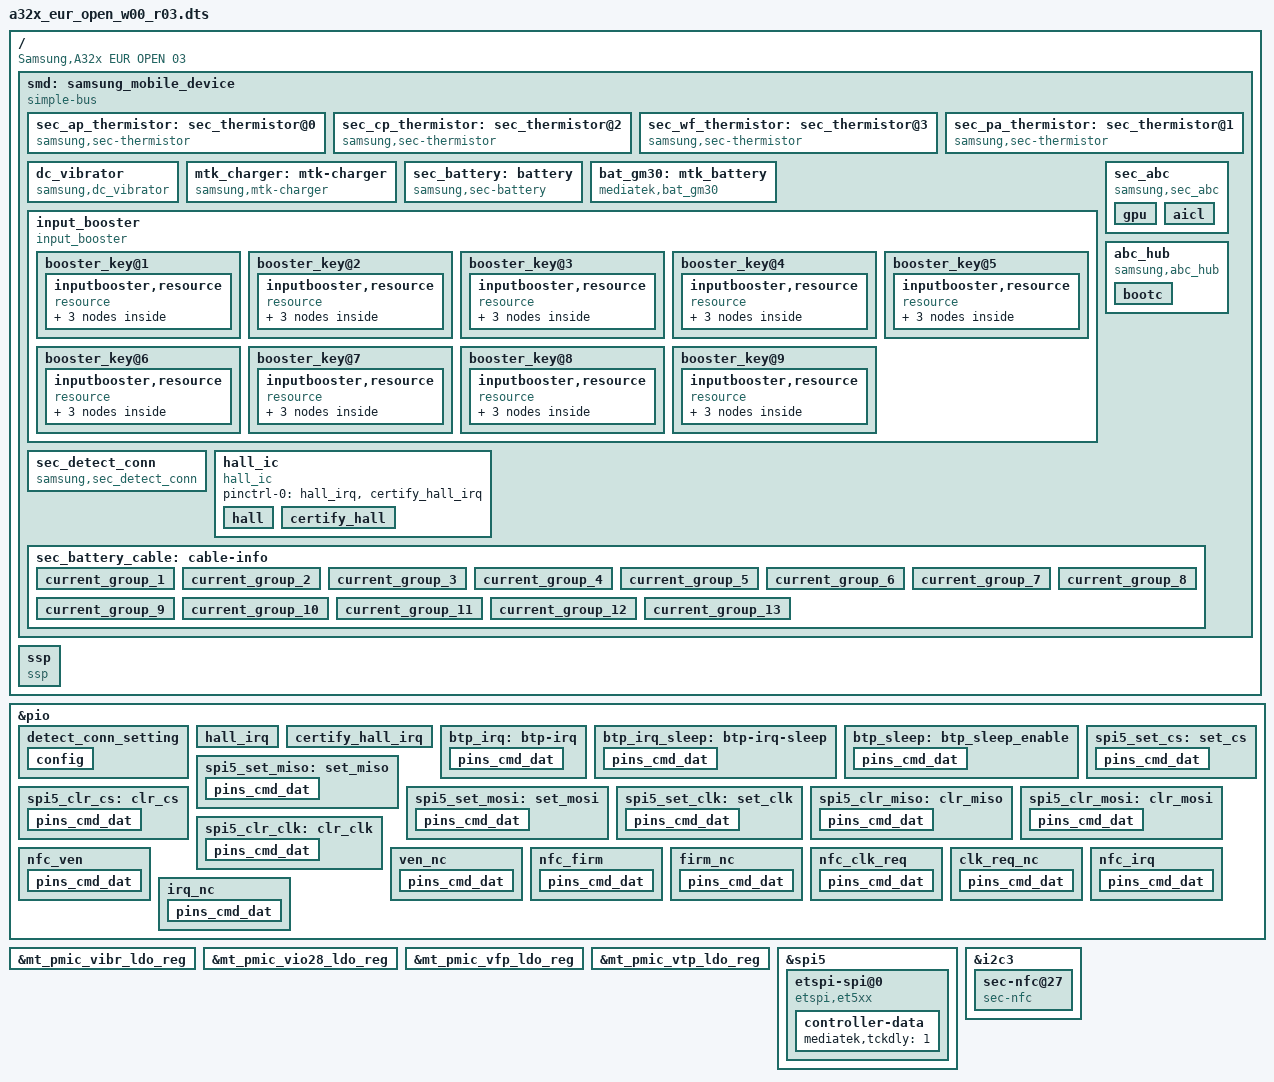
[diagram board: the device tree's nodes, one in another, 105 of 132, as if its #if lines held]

/*
 * Copyright (c) 2018 Samsung Electronics Co., Ltd.
 *              http://www.samsung.com
 *
 * This program is free software; you can redistribute it and/or modify
 * it under the terms of the GNU General Public License version 2 as
 * published by the Free Software Foundation.
*/

/dts-v1/;
/plugin/;
/ {
	fragment@smd {
		target-path = "/";
		__overlay__ {
			smd: samsung_mobile_device {
				compatible = "simple-bus";
			};
		};
	};
};

/* #include "../mtk_charger.dtsi" */                 /* From mtk_charger.py */

&smd {
	mtk_charger: mtk-charger {
		compatible = "samsung,mtk-charger";
		charger,vbus_min_charger_voltage = <4600000>;
		charger,vbus_normal_mivr_voltage = <4400000>;
		charger,gpio_ilim = <&pio 140 0x0>;
		charger,gpio_chgenb = <&pio 135 0x0>;
		charger,max_icl = <3250>;
		charger,ib_fcc = <100>;
	};
};

/* /home/dpi/qb5_8815/workspace/P4_1716/android/kernel/kmodule/battery/charger/mtk_charger/mtk_charger.a32x_eur_open.01.dtsi */

&smd {
	mtk_charger: mtk-charger {
		charger,chgenb_en = <1>;
	};
};


/* #include "../mtk_fuelgauge.dtsi" */               /* From mtk_fuelgauge.py */
&smd {
	battery {
		battery,fuelgauge_name = "mtk-fg-battery";
	};

	/* battery_prop.dtsi */
	bat_gm30: mtk_battery{
		compatible = "mediatek,bat_gm30";
		DIFFERENCE_FULLOCV_ITH = <(300)>;
	/*	Charging termination current*/
		SHUTDOWN_1_TIME = <(60)>;
	/*	If ui_soc shows 1% more than X minites, system will shutdown*/
		KEEP_100_PERCENT = <(1)>;
	/* 	The ui_soc will keep 100% until SOC drop X percents after unplugged */
		R_FG_VALUE = <(5)>;
	/*	R_sense resistance*/
		EMBEDDED_SEL = <(0)>;
	/*	Configures whether using embedded battery or not*/
		PMIC_SHUTDOWN_CURRENT = <(20)>;
	/*	System shutdown current*/
		FG_METER_RESISTANCE = <(100)>;
	/*	The resistance of PCB*/
		CAR_TUNE_VALUE = <(99)>;
	/*	Tune value for current measurement*/
		PMIC_MIN_VOL = <(33500)>;
	/*	vboot voltage for gauge 0%*/
		POWERON_SYSTEM_IBOOT = <(500)>;
	/*	power on system iboot*/
		SHUTDOWN_GAUGE0 = <(0)>;
	/*	Shutdown condition2 switch*/
		SHUTDOWN_GAUGE0_VOLTAGE = <(34000)>;
	/*	shutdown gauge 0% voltage*/
		TEMPERATURE_T0 = <(50)>;
	/*	Battery temperature T0*/
		TEMPERATURE_T1 = <(25)>;
	/*	Battery temperature T1*/
		TEMPERATURE_T2 = <(10)>;
	/*	Battery temperature T2*/
		TEMPERATURE_T3 = <(0)>;
	/*	Battery temperature T3*/
		TEMPERATURE_T4 = <(-10)>;
	/*	Battery temperature T4*/
		TEMPERATURE_T5 = <(-20)>;
	/*	Battery temperature T5*/
		g_FG_PSEUDO100_T0 = <(93)>;
	/*	Pseudo 100% percentage at T0*/
		g_FG_PSEUDO100_T1 = <(93)>;
	/*	Pseudo 100% percentage at T1*/
		g_FG_PSEUDO100_T2 = <(93)>;
	/*	Pseudo 100% percentage at T2*/
		g_FG_PSEUDO100_T3 = <(93)>;
	/*	Pseudo 100% percentage at T3*/
		g_FG_PSEUDO100_T4 = <(93)>;
	/*	Pseudo 100% percentage at T4*/
		g_FG_PSEUDO100_T5 = <(93)>;
	/*	Pseudo 100% percentage at T4*/
		Q_MAX_SYS_VOLTAGE_BAT0 = <(3350)>;
	/*	Pseudo1 for hide percentage*/
		Q_MAX_SYS_VOLTAGE_BAT1 = <(3350)>;
	/*	Pseudo1 for hide percentage*/
		Q_MAX_SYS_VOLTAGE_BAT2 = <(3350)>;
	/*	Pseudo1 for hide percentage*/
		Q_MAX_SYS_VOLTAGE_BAT3 = <(3350)>;
	/*	Pseudo1 for hide percentage*/
		COM_FG_METER_RESISTANCE = <(100)>;
	/*	compensate The resistance of PCB*/
		COM_R_FG_VALUE = <(0)>;
	/*	compensate R_sense resistance*/
		enable_tmp_intr_suspend = <(0)>;
	/* Enable update temp when suspend */
		ACTIVE_TABLE = <(6)>;
	/* Table numbers per battery*/
		MULTI_TEMP_GAUGE0 = <(1)>;
	/* Multi gauge0 enable*/
		HWOCV_OLDOCV_DIFF = <(100)>;
	/* Diff of HWOCV and SWOCV*/

	/* battery_table.dtsi*/
	battery0_profile_t0_num = <100>;
	battery0_profile_t0_col = <3>;
	battery0_profile_t0 =
	<
	0       43520   850
	486     43380   866
	972     43251   875
	1458    43130   897
	1944    43004   875
	2430    42881   875
	2916    42760   875
	3402    42644   875
	3888    42530   900
	4375    42407   875
	4861    42293   881
	5347    42178   900
	5833    42054   875
	6319    41941   897
	6805    41820   875
	7291    41714   875
	7777    41601   900
	8263    41485   875
	8749    41372   875
	9235    41267   897
	9721    41155   875
	10207   41051   875
	10693   40945   875
	11179   40837   884
	11665   40739   875
	12152   40642   900
	12638   40542   894
	13124   40446   919
	13610   40350   900
	14096   40253   900
	14582   40162   919
	15068   40070   925
	15554   39979   925
	16040   39898   941
	16526   39817   950
	17012   39736   950
	17498   39655   962
	17984   39573   975
	18470   39492   975
	18956   39411   1000
	19442   39329   1025
	19928   39210   975
	20415   39078   938
	20901   38949   878
	21387   38849   875
	21873   38773   850
	22359   38699   850
	22845   38635   850
	23331   38580   850
	23817   38521   850
	24303   38472   850
	24789   38423   850
	25275   38374   875
	25761   38326   850
	26247   38285   869
	26733   38239   850
	27219   38200   875
	27705   38157   866
	28192   38115   868
	28678   38082   872
	29164   38050   875
	29650   38007   853
	30136   37975   875
	30622   37952   900
	31108   37919   900
	31594   37887   900
	32080   37865   907
	32566   37841   925
	33052   37810   925
	33538   37765   900
	34024   37684   861
	34510   37614   865
	34996   37550   851
	35482   37511   859
	35968   37465   857
	36455   37424   853
	36941   37374   850
	37427   37337   875
	37913   37304   875
	38399   37272   875
	38885   37230   875
	39371   37185   900
	39857   37120   875
	40343   37063   875
	40829   37004   888
	41315   36942   879
	41801   36861   881
	42287   36806   860
	42773   36790   875
	43259   36780   891
	43745   36767   907
	44232   36751   948
	44718   36719   976
	45204   36643   1018
	45690   36372   937
	46176   35944   969
	46662   35387   1000
	47148   34581   1041
	47634   33318   1181
	48120   30130   10325
	>;
	battery0_profile_t1_num = <100>;
	battery0_profile_t1_col = <3>;
	battery0_profile_t1 =
	<
	0       43320   1450
	486     43164   1450
	972     43033   1475
	1458    42911   1475
	1944    42789   1475
	2430    42671   1475
	2916    42550   1456
	3402    42434   1475
	3888    42320   1475
	4375    42197   1440
	4861    42083   1431
	5347    41968   1428
	5833    41854   1437
	6319    41741   1428
	6805    41628   1431
	7291    41514   1425
	7777    41401   1425
	8263    41295   1425
	8749    41184   1407
	9235    41078   1403
	9721    40975   1412
	10207   40871   1425
	10693   40765   1425
	11179   40667   1416
	11665   40569   1425
	12152   40475   1450
	12638   40382   1450
	13124   40277   1450
	13610   40190   1450
	14096   40093   1447
	14582   40002   1444
	15068   39920   1460
	15554   39839   1450
	16040   39758   1450
	16526   39687   1500
	17012   39606   1500
	17498   39525   1500
	17984   39443   1504
	18470   39354   1525
	18956   39243   1490
	19442   39109   1425
	19928   38980   1344
	20415   38875   1319
	20901   38787   1300
	21387   38719   1313
	21873   38654   1300
	22359   38589   1300
	22845   38535   1290
	23331   38480   1300
	23817   38431   1291
	24303   38384   1300
	24789   38343   1300
	25275   38294   1300
	25761   38257   1303
	26247   38217   1325
	26733   38182   1309
	27219   38140   1325
	27705   38107   1341
	28192   38075   1332
	28678   38042   1350
	29164   38010   1350
	29650   37987   1375
	30136   37955   1375
	30622   37926   1375
	31108   37900   1376
	31594   37877   1384
	32080   37855   1400
	32566   37822   1378
	33052   37790   1375
	33538   37747   1375
	34024   37707   1356
	34510   37672   1360
	34996   37630   1351
	35482   37591   1359
	35968   37552   1350
	36455   37512   1372
	36941   37480   1375
	37427   37447   1375
	37913   37414   1394
	38399   37368   1385
	38885   37310   1376
	39371   37248   1393
	39857   37192   1400
	40343   37134   1423
	40829   37063   1412
	41315   36975   1425
	41801   36935   1425
	42287   36920   1460
	42773   36910   1475
	43259   36894   1500
	43745   36867   1514
	44232   36833   1573
	44718   36727   1613
	45204   36421   1607
	45690   35937   1688
	46176   35299   1804
	46662   34415   1951
	47148   32710   2488
	47634   30570   11550
	48120   30570   11550
	>;
	battery0_profile_t2_num = <100>;
	battery0_profile_t2_col = <3>;
	battery0_profile_t2 =
	<
	0       43000   3200
	486     42808   3293
	972     42661   3412
	1458    42531   3472
	1944    42404   3476
	2430    42281   3478
	2916    42160   3481
	3402    42044   3484
	3888    41930   3475
	4375    41817   3485
	4861    41695   3456
	5347    41579   3431
	5833    41474   3450
	6319    41361   3425
	6805    41255   3425
	7291    41144   3425
	7777    41041   3425
	8263    40931   3416
	8749    40834   3407
	9235    40737   3425
	9721    40640   3425
	10207   40541   3444
	10693   40435   3419
	11179   40337   3425
	11665   40229   3375
	12152   40138   3391
	12638   40047   3381
	13124   39957   3378
	13610   39875   3400
	14096   39794   3375
	14582   39712   3375
	15068   39640   3415
	15554   39559   3425
	16040   39472   3409
	16526   39382   3425
	17012   39269   3381
	17498   39146   3350
	17984   39008   3268
	18470   38894   3225
	18956   38801   3200
	19442   38720   3200
	19928   38655   3200
	20415   38590   3200
	20901   38534   3222
	21387   38479   3225
	21873   38426   3250
	22359   38377   3250
	22845   38329   3275
	23331   38280   3275
	23817   38241   3300
	24303   38202   3325
	24789   38162   3347
	25275   38130   3363
	25761   38087   3378
	26247   38055   3400
	26733   38022   3425
	27219   37990   3425
	27705   37967   3466
	28192   37935   3500
	28678   37911   3500
	29164   37885   3525
	29650   37859   3528
	30136   37842   3569
	30622   37822   3600
	31108   37800   3601
	31594   37784   3641
	32080   37757   3657
	32566   37732   3697
	33052   37700   3700
	33538   37667   3728
	34024   37627   3750
	34510   37592   3795
	34996   37559   3850
	35482   37517   3866
	35968   37482   3932
	36455   37434   3972
	36941   37374   4026
	37427   37314   4104
	37913   37249   4144
	38399   37190   4235
	38885   37119   4325
	39371   37028   4398
	39857   36965   4501
	40343   36932   4666
	40829   36905   4816
	41315   36877   5048
	41801   36845   5310
	42287   36790   5653
	42773   36689   6028
	43259   36466   6433
	43745   36033   6914
	44232   35419   7720
	44718   34544   8974
	45204   33115   11297
	45690   30950   12525
	46176   30950   12525
	46662   30950   12525
	47148   30950   12525
	47634   30950   12525
	48120   30950   12525
	>;
	battery0_profile_t3_num = <100>;
	battery0_profile_t3_col = <3>;
	battery0_profile_t3 =
	<
	0       42520   5950
	486     42262   6183
	972     42098   6518
	1458    41961   6640
	1944    41824   6714
	2430    41701   6753
	2916    41580   6775
	3402    41464   6816
	3888    41350   6825
	4375    41237   6840
	4861    41123   6825
	5347    41017   6847
	5833    40909   6825
	6319    40812   6847
	6805    40715   6844
	7291    40604   6825
	7777    40501   6825
	8263    40385   6784
	8749    40274   6782
	9235    40177   6800
	9721    40080   6800
	10207   39984   6778
	10693   39903   6781
	11179   39821   6784
	11665   39739   6800
	12152   39658   6791
	12638   39587   6825
	13124   39497   6803
	13610   39410   6813
	14096   39312   6797
	14582   39196   6756
	15068   39069   6680
	15554   38949   6625
	16040   38836   6584
	16526   38747   6569
	17012   38666   6550
	17498   38600   6575
	17984   38536   6579
	18470   38479   6600
	18956   38418   6635
	19442   38370   6675
	19928   38321   6691
	20415   38275   6706
	20901   38234   6725
	21387   38194   6750
	21873   38156   6775
	22359   38115   6794
	22845   38082   6835
	23331   38050   6850
	23817   38018   6891
	24303   37984   6907
	24789   37952   6925
	25275   37930   6975
	25761   37909   7003
	26247   37892   7044
	26733   37876   7084
	27219   37860   7125
	27705   37843   7183
	28192   37827   7214
	28678   37811   7295
	29164   37795   7351
	29650   37777   7407
	30136   37752   7488
	30622   37722   7544
	31108   37689   7626
	31594   37657   7723
	32080   37622   7813
	32566   37582   7939
	33052   37540   8076
	33538   37495   8238
	34024   37437   8422
	34510   37374   8610
	34996   37309   8853
	35482   37238   9080
	35968   37170   9352
	36455   37096   9676
	36941   37004   10017
	37427   36935   10393
	37913   36894   10858
	38399   36862   11389
	38885   36830   11982
	39371   36791   12670
	39857   36740   13453
	40343   36656   14301
	40829   36424   15025
	41315   35986   15823
	41801   35349   16953
	42287   34442   18475
	42773   33430   18575
	43259   33430   18575
	43745   33430   18575
	44232   33430   18575
	44718   33430   18575
	45204   33430   18575
	45690   33430   18575
	46176   33430   18575
	46662   33430   18575
	47148   33430   18575
	47634   33430   18575
	48120   33430   18575
	>;
	battery0_profile_t4_num = <100>;
	battery0_profile_t4_col = <3>;
	battery0_profile_t4 =
	<
	0       42010   11330
	486     41738   11604
	972     41429   12066
	1458    41171   12469
	1944    40989   12751
	2430    40838   12878
	2916    40700   12919
	3402    40570   12916
	3888    40440   12875
	4375    40311   12819
	4861    40181   12744
	5347    40058   12703
	5833    39949   12675
	6319    39842   12650
	6805    39745   12650
	7291    39648   12616
	7777    39541   12526
	8263    39441   12509
	8749    39332   12437
	9235    39227   12378
	9721    39115   12312
	10207   39013   12272
	10693   38923   12250
	11179   38841   12216
	11665   38759   12200
	12152   38694   12184
	12638   38622   12175
	13124   38565   12175
	13610   38510   12200
	14096   38456   12178
	14582   38407   12200
	15068   38358   12210
	15554   38310   12225
	16040   38261   12241
	16526   38215   12256
	17012   38174   12297
	17498   38140   12325
	17984   38097   12329
	18470   38065   12350
	18956   38032   12375
	19442   38010   12450
	19928   37977   12475
	20415   37955   12506
	20901   37931   12568
	21387   37905   12626
	21873   37874   12675
	22359   37855   12770
	22845   37832   12819
	23331   37800   12900
	23817   37778   13031
	24303   37744   13121
	24789   37712   13242
	25275   37670   13327
	25761   37626   13460
	26247   37577   13639
	26733   37535   13728
	27219   37480   13875
	27705   37420   14031
	28192   37359   14202
	28678   37294   14386
	29164   37230   14552
	29650   37155   14720
	30136   37090   14944
	30622   37028   15148
	31108   36979   15354
	31594   36947   15613
	32080   36905   15847
	32566   36863   16130
	33052   36790   16376
	33538   36673   16644
	34024   36429   16891
	34510   36018   17215
	34996   35399   17761
	35482   34431   18699
	35968   32802   17069
	36455   31080   12750
	36941   31080   12750
	37427   31080   12750
	37913   31080   12750
	38399   31080   12750
	38885   31080   12750
	39371   31080   12750
	39857   31080   12750
	40343   31080   12750
	40829   31080   12750
	41315   31080   12750
	41801   31080   12750
	42287   31080   12750
	42773   31080   12750
	43259   31080   12750
	43745   31080   12750
	44232   31080   12750
	44718   31080   12750
	45204   31080   12750
	45690   31080   12750
	46176   31080   12750
	46662   31080   12750
	47148   31080   12750
	47634   31080   12750
	48120   31080   12750
	>;
	battery0_profile_t5_num = <100>;
	battery0_profile_t5_col = <3>;
	battery0_profile_t5 =
	<
	0       40920   10780
	483     40610   11233
	967     40337   12231
	1450    40095   12975
	1933    39872   13686
	2417    39674   14479
	2900    39510   15208
	3383    39378   15667
	3867    39258   15931
	4350    39150   16075
	4833    39042   16178
	5317    38929   16164
	5800    38830   16208
	6283    38733   16319
	6767    38652   16378
	7250    38573   16404
	7733    38509   16464
	8217    38444   16519
	8700    38390   16625
	9183    38335   16666
	9667    38292   16706
	10150   38244   16725
	10633   38200   16750
	11117   38158   16752
	11600   38126   16810
	12083   38087   16833
	12567   38052   16965
	13050   38019   16990
	13533   37987   17100
	14017   37955   17176
	14500   37919   17218
	14983   37880   17323
	15467   37838   17390
	15950   37794   17510
	16433   37738   17550
	16917   37683   17714
	17400   37629   17828
	17883   37564   17981
	18367   37500   18070
	18850   37427   18222
	19333   37361   18385
	19817   37286   18407
	20300   37222   18563
	20783   37158   18764
	21267   37093   18919
	21750   37039   19080
	22233   36974   19247
	22717   36910   19451
	23200   36824   19655
	23683   36692   19921
	24167   36470   20134
	24650   36118   20420
	25133   35546   20803
	25617   34662   21167
	26100   33270   18200
	26583   32530   16450
	27067   32530   16450
	27550   32530   16450
	28033   32530   16450
	28517   32530   16450
	29000   32530   16450
	29483   32530   16450
	29967   32530   16450
	30450   32530   16450
	30933   32530   16450
	31417   32530   16450
	31900   32530   16450
	32383   32530   16450
	32867   32530   16450
	33350   32530   16450
	33833   32530   16450
	34317   32530   16450
	34800   32530   16450
	35283   32530   16450
	35767   32530   16450
	36250   32530   16450
	36733   32530   16450
	37217   32530   16450
	37700   32530   16450
	38183   32530   16450
	38667   32530   16450
	39150   32530   16450
	39633   32530   16450
	40117   32530   16450
	40600   32530   16450
	41083   32530   16450
	41567   32530   16450
	42050   32530   16450
	42533   32530   16450
	43017   32530   16450
	43500   32530   16450
	43983   32530   16450
	44467   32530   16450
	44950   32530   16450
	45433   32530   16450
	45917   32530   16450
	46400   32530   16450
	46883   32530   16450
	47367   32530   16450
	47850   32530   16450
	>;

	/* battery_prop_dim2_ext.dtsi */
	/*vboot voltage for gauge 0%*/
	g_PMIC_MIN_VOL_row = <4>;
	g_PMIC_MIN_VOL_col = <10>;
	g_PMIC_MIN_VOL =
	<
		32700  32700  32700  32700
		32700  32700  32700  32700
		32700  32700  32700  32700
		32200  32200  32200  32200
		31000  31000  31000  31000
		31500  31500  31500  31500
		31000  31000  31000  31000
		31000  31000  31000  31000
		31000  31000  31000  31000
		31000  31000  31000  31200
	>;
	/*boot_up current for gauge 0%*/
	g_PON_SYS_IBOOT_row = <4>;
	g_PON_SYS_IBOOT_col = <10>;
	g_PON_SYS_IBOOT =
	<
		5000  5000  5000  5000
		5000  5000  5000  5000
		5000  5000  5000  5000
		5000  5000  5000  5000
		5000  5000  5000  5000
		5000  5000  5000  5000
		5000  5000  5000  5000
		5000  5000  5000  5000
		5000  5000  5000  5000
		5000  5000  5000  5000
	>;
	/*Pseudo1 hide percentage*/
	g_QMAX_SYS_VOL_row = <4>;
	g_QMAX_SYS_VOL_col = <10>;
	g_QMAX_SYS_VOL =
	<
		33600  33600  33600  33600
		33600  33600  33600  33600
		33600  33600  33600  33600
		33600  33600  33600  33600
		33600  33600  33600  33600
		32500  32500  32500  32500
		32800  32800  32800  32800
		32800  32800  32800  32800
		32800  32800  32800  32800
		32800  32800  32800  32800
	>;
	/*Pseudo100 percentage setting*/
	g_FG_PSEUDO100_row = <4>;
	g_FG_PSEUDO100_col = <10>;
	g_FG_PSEUDO100 =
	<
		 93  100  100  100
		 93  100  100  100
		 93  100  100  100
		 93  100  100  100
		 93  100  100  100
		 93  100  100  100
		100  100  100  100
		100  100  100  100
		100  100  100  100
		100  100  100  100
	>;

	};
};

/* /home/dpi/qb5_8815/workspace/P4_1716/android/kernel/kmodule/battery/fuelgauge/mtk_fuelgauge/mtk_fuelgauge.a32x_eur_open.01.dtsi */
&smd {
	bat_gm30: mtk_battery{
		/* The ui_soc will keep 100% until SOC drop X percents after unplugged */
		R_FG_VALUE = <(5)>;
	};
};

/* #include "../sec_pinctrl_wrapper.dtsi" */         /* From sec_pinctrl_wrapper.py */
#define PIN_FUNC_INPUT		input-enable
#define PIN_FUNC_INPUT_WAKEUP	input-enable
#define PIN_FUNC_OUTPUT		output-enable
#define PIN_FUNC_OUTPUT_HIGH		output-high
#define PIN_FUNC_OUTPUT_LOW		output-low

#define PIN_PULL_NONE	bias-disable
#define PIN_PULL_DOWN	bias-pull-down
#define PIN_PULL_UP	bias-pull-up
#define PIN_PULL_OPEN	bias-high-impedance

/*
 * MTK_DRIVE_2mA  2
 * MTK_DRIVE_4mA  4
 * MTK_DRIVE_6mA  6
 * MTK_DRIVE_8mA  8
 * MTK_DRIVE_10mA 10
 * MTK_DRIVE_12mA 12
 * MTK_DRIVE_14mA 14
 * MTK_DRIVE_16mA 16
 */

#define PIN_DRV_LV1	2
#define PIN_DRV_LV2	4
#define PIN_DRV_LV3	6
#define PIN_DRV_LV4	8
#define PIN_DRV_LV5	10
#define PIN_DRV_LV6	12
#define PIN_DRV_LV7	14
#define PIN_DRV_LV8	16

#define PIN_EXPAND(pin) #pin

#define SEC_GPIO(src, type, num)	PIN_EXPAND(gpio##num)
#define SEC_GPIO_REF(src, type, num)	&type num
#define SEC_GPIO_NUM(src, type, num)	num
#define SEC_GPIO_TYPE(src, type, num)	&type

#define MTK_PINMUX(gpio, func) (MTK_PIN_NO(gpio) | func)

#define GPIO_CONFIG(_src, _type, _num, _func)		\
	pins_cmd_dat{					\
		pinmux = <MTK_PINMUX(SEC_GPIO_NUM(_src, _type, _num), 0)>;	\
		PIN_ ##_func;		\
	}

#define GPIO_CONFIG_PUD(_src, _type, _num, _func, _pull)	\
	pins_cmd_dat{					\
		pinmux = <MTK_PINMUX(SEC_GPIO_NUM(_src, _type, _num), 0)>;	\
		PIN_ ##_pull;				\
		PIN_ ##_func;		\
	}

#define GPIO_CONFIG_PUD_DRV(_src, _type, _num, _func, _pull, _drv)	\
	pins_cmd_dat{					\
		pinmux = <MTK_PINMUX(SEC_GPIO_NUM(_src, _type, _num), 0)>;	\
		PIN_ ##_pull;				\
		PIN_ ##_func;		\
		drive-strength = <PIN_ ##_drv>;	\
	}

#define SEC_ADC(type, num) <&type num>
#define SEC_ADC_OPT(type, num) ,<&type num>
#define SEC_ADC_NUM(type, num) <num>

/* #include "../input_booster.dtsi" */               /* From input_booster.py */
/* Copyright (c) 2019, The Linux Foundation. All rights reserved.
 *
 * This program is free software; you can redistribute it and/or modify
 * it under the terms of the GNU General Public License version 2 and
 * only version 2 as published by the Free Software Foundation.
 *
 * This program is distributed in the hope that it will be useful,
 * but WITHOUT ANY WARRANTY; without even the implied warranty of
 * MERCHANTABILITY or FITNESS FOR A PARTICULAR PURPOSE.  See the
 * GNU General Public License for more details.
 */

&smd {
	input_booster {
		status = "okay";
		compatible = "input_booster";
		resValcount = "2";
		max_resource_count = "3";
		max_cluster_count = "3";
		#address-cells = <1>;
		#size-cells = <0>;

		/* Each Cpu Cluster Start Cpu */
		cpu_cluster_policy = "6,0";

		/* < CPU, DDR, SCHEDBOOST > */
		ib_release_values = "-1,16,0";

		/* Select Allowed Resource Index Group */
		allowed_resources = "0,1,2";

		booster_key@1 {
			input_booster,label = "key";
			input_booster,type = <0>;	/* BOOSTER_DEVICE_KEY */

			/* Time table */
			input_booster,head_time = <200>;
			input_booster,tail_time = <0>;

			/* Resource Table Sequentially identified with index
			 * CPU's ID & Index : 0
			 * DDR's ID & Index : 1
			*/

			/* Input Booster Resource Frequency */
			inputbooster,resource {
				compatible = "resource";
				resource@1 {
					resource,label = "CPU";
					resource,value = <1274000 0>;
				};

				resource@2 {
					resource,label = "DDR";
					resource,value = <0 0>;
				};

				resource@3 {
					resource,label = "SCHEDBOOST";
					resource,value = <0 0>;
				};
			};
		};

		booster_key@2 {
			input_booster,label = "touchkey";
			input_booster,type = <1>;	/* BOOSTER_DEVICE_TOUCHKEY */

			/* Time table */
			input_booster,head_time = <1>;
			input_booster,tail_time = <300>;

			/* Input Booster Resource Frequency */
			inputbooster,resource {
				compatible = "resource";
				resource@1 {
					resource,label = "CPU";
					resource,value = <0 1075200>;
				};

				resource@2 {
					resource,label = "DDR";
					resource,value = <0 0>;
				};

				resource@3 {
					resource,label = "SCHEDBOOST";
					resource,value = <0 0>;
				};
			};
		};

		booster_key@3 {
			input_booster,label = "touch";
			input_booster,type = <2>;	/* BOOSTER_DEVICE_TOUCH */

			/* Time table */
			input_booster,head_time = <130>;
			input_booster,tail_time = <500>;

			/* Input Booster Resource Frequency */
			inputbooster,resource {
				compatible = "resource";
				resource@1 {
					resource,label = "CPU";
					resource,value = <1274000 1075200>;
				};

				resource@2 {
					resource,label = "DDR";
					resource,value = <4266 4266>;
				};

				resource@3 {
					resource,label = "SCHEDBOOST";
					resource,value = <3 0>;
				};
			};
		};

		booster_key@4 {
			input_booster,label = "multitouch";
			input_booster,type = <3>;	/* BOOSTER_DEVICE_MULTITOUCH */

			/* Time table */
			input_booster,head_time = <1000>;
			input_booster,tail_time = <500>;

			/* Input Booster Resource Frequency */
			inputbooster,resource {
				compatible = "resource";
				resource@1 {
					resource,label = "CPU";
					resource,value = <1274000 1075200>;
				};

				resource@2 {
					resource,label = "DDR";
					resource,value = <0 0>;
				};

				resource@3 {
					resource,label = "SCHEDBOOST";
					resource,value = <0 0>;
				};
			};
		};

		booster_key@5 {
			input_booster,label = "keyboard";
			input_booster,type = <4>;	/* BOOSTER_DEVICE_KEYBOARD */

			/* Time table */
			input_booster,head_time = <130>;
			input_booster,tail_time = <130>;

			/* Input Booster Resource Frequency */
			inputbooster,resource {
				compatible = "resource";
				resource@1 {
					resource,label = "CPU";
					resource,value = <1075200 1075200>;
				};

				resource@2 {
					resource,label = "DDR";
					resource,value = <0 0>;
				};

				resource@3 {
					resource,label = "SCHEDBOOST";
					resource,value = <0 0>;
				};
			};
		};

		booster_key@6 {
			input_booster,label = "MOUSE";
			input_booster,type = <5>;	/* BOOSTER_DEVICE_MOUSE */

			/* Time table */
			input_booster,head_time = <200>;
			input_booster,tail_time = <300>;

			/* Input Booster Resource Frequency */
			inputbooster,resource {
				compatible = "resource";
				resource@1 {
					resource,label = "CPU";
					resource,value = <1274000 1075200>;
				};

				resource@2 {
					resource,label = "DDR";
					resource,value = <0 0>;
				};

				resource@3 {
					resource,label = "SCHEDBOOST";
					resource,value = <0 0>;
				};
			};
		};

		booster_key@7 {
			input_booster,label = "mouse_wheel";
			input_booster,type = <6>;	/* BOOSTER_DEVICE_MOUSE */

			/* Time table */
			input_booster,head_time = <200>;
			input_booster,tail_time = <0>;

			/* Input Booster Resource Frequency */
			inputbooster,resource {
				compatible = "resource";
				resource@1 {
					resource,label = "CPU";
					resource,value = <1274000 0>;
				};

				resource@2 {
					resource,label = "DDR";
					resource,value = <0 0>;
				};

				resource@3 {
					resource,label = "SCHEDBOOST";
					resource,value = <0 0>;
				};
			};
		};

		booster_key@8 {
			input_booster,label = "pen_hover";
			input_booster,type = <7>;	/* BOOSTER_DEVICE_MOUSE */

			/* Time table */
			input_booster,head_time = <200>;
			input_booster,tail_time = <300>;

			/* Input Booster Resource Frequency */
			inputbooster,resource {
				compatible = "resource";
				resource@1 {
					resource,label = "CPU";
					resource,value = <1274000 1075200>;
				};

				resource@2 {
					resource,label = "DDR";
					resource,value = <0 0>;
				};

				resource@3 {
					resource,label = "SCHEDBOOST";
					resource,value = <0 0>;
				};
			};
		};

		booster_key@9 {
			input_booster,label = "pen";
			input_booster,type = <8>;	/* BOOSTER_DEVICE_MOUSE */

			/* Time table */
			input_booster,head_time = <200>;
			input_booster,tail_time = <600>;

			/* Input Booster Resource Frequency */
			inputbooster,resource {
				compatible = "resource";
				resource@1 {
					resource,label = "CPU";
					resource,value = <1720000 1075200>;
				};

				resource@2 {
					resource,label = "DDR";
					resource,value = <0 0>;
				};

				resource@3 {
					resource,label = "SCHEDBOOST";
					resource,value = <0 0>;
				};
			};
		};
		/* If you need to add new key type, add it this position */
	};
};

/* #include "../sti_abc.dtsi" */                     /* From sti_abc.py */
#ifndef CONFIG_SEC_FACTORY

#if 0
&${gpio_sub_connect_conn_parent} {
	sub_detect_conn_setting: sub-detect-conn-setting {
		samsung,pins = SEC_GPIO(${gpio_sub_connect_conn});
		samsung,pin-function = <0xf>;
		samsung,pin-pud = <0>;
		samsung,pin-drv = <0>;
	};
};
#endif

#if 0
&${gpio_sub_connect_conn_parent2} {
	sub_detect_conn_setting2: sub-detect-conn-setting2 {
		samsung,pins = SEC_GPIO(${gpio_sub_connect_conn2});
		samsung,pin-function = <0xf>;
		samsung,pin-pud = <0>;
		samsung,pin-drv = <0>;
	};
};
#endif

#if 0
&${gpio_cam_connect_conn_parent} {
	cam_detect_conn_setting: cam-detect-conn-setting {
		samsung,pins = SEC_GPIO(${gpio_cam_connect_conn});
		samsung,pin-function = <0xf>;
		samsung,pin-pud = <0>;
		samsung,pin-drv = <0>;
	};
};
#endif

#if 0
&${det_gpio_num_parent} {
	detect_conn_setting: detect_conn_setting {
		config {
#if 0
			pins = SEC_GPIO(${det_gpio_num_0}),
			       SEC_GPIO(${det_gpio_num_1}),
			       SEC_GPIO(${det_gpio_num_2}),
			       SEC_GPIO(${det_gpio_num_3}),
			       SEC_GPIO(${det_gpio_num_4}),
#if 0
			       SEC_GPIO(${det_gpio_num_5}),
			       SEC_GPIO(${det_gpio_num_6}),
			       SEC_GPIO(${det_gpio_num_7});
#elif 0
			       SEC_GPIO(${det_gpio_num_5}),
			       SEC_GPIO(${det_gpio_num_6});
#else
			       SEC_GPIO(${det_gpio_num_5});
#endif
#elif 0
			pins = SEC_GPIO(${det_gpio_num_0}),
			       SEC_GPIO(${det_gpio_num_1}),
			       SEC_GPIO(${det_gpio_num_2}),
			       SEC_GPIO(${det_gpio_num_3}),
#if 0
			       SEC_GPIO(${det_gpio_num_4}),
			       SEC_GPIO(${det_gpio_num_6}),
			       SEC_GPIO(${det_gpio_num_7});
#elif 0
			       SEC_GPIO(${det_gpio_num_4}),
			       SEC_GPIO(${det_gpio_num_6});
#else
			       SEC_GPIO(${det_gpio_num_4});
#endif
#elif 0
			pins = SEC_GPIO(${det_gpio_num_0}),
			       SEC_GPIO(${det_gpio_num_1}),
			       SEC_GPIO(${det_gpio_num_2}),
#if 0
			       SEC_GPIO(${det_gpio_num_3}),
			       SEC_GPIO(${det_gpio_num_6}),
			       SEC_GPIO(${det_gpio_num_7});
#elif 0
			       SEC_GPIO(${det_gpio_num_3}),
			       SEC_GPIO(${det_gpio_num_6});
#else
			       SEC_GPIO(${det_gpio_num_3});
#endif
#elif 0
			pins = SEC_GPIO(${det_gpio_num_0}),
			       SEC_GPIO(${det_gpio_num_1}),
#if 0
			       SEC_GPIO(${det_gpio_num_2}),
			       SEC_GPIO(${det_gpio_num_6}),
			       SEC_GPIO(${det_gpio_num_7});
#elif 0
			       SEC_GPIO(${det_gpio_num_2}),
			       SEC_GPIO(${det_gpio_num_6});
#else
			       SEC_GPIO(${det_gpio_num_2});
#endif
#elif 0
			pins = SEC_GPIO(${det_gpio_num_0}),
#if 0
			       SEC_GPIO(${det_gpio_num_1}),
			       SEC_GPIO(${det_gpio_num_6}),
			       SEC_GPIO(${det_gpio_num_7});
#elif 0
			       SEC_GPIO(${det_gpio_num_1}),
			       SEC_GPIO(${det_gpio_num_6});
#else
			       SEC_GPIO(${det_gpio_num_1});
#endif
#elif 0
			pins =
#if 0
			       SEC_GPIO(${det_gpio_num_0}),
			       SEC_GPIO(${det_gpio_num_6}),
			       SEC_GPIO(${det_gpio_num_7});
#elif 0
			       SEC_GPIO(${det_gpio_num_0}),
			       SEC_GPIO(${det_gpio_num_6});
#else
			       SEC_GPIO(${det_gpio_num_0});
#endif
#elif 0
			pins = SEC_GPIO(${det_gpio_num_6}),
			       SEC_GPIO(${det_gpio_num_7});
#elif 0
			pins = SEC_GPIO(${det_gpio_num_6});
#endif
			drive-strength = <2>;
			bias-disable; /*NO PULL*/
			input-enable;
		};
	};
};
#endif /*use_dynamic_ap_gpio_detect*/

#if 0
&${det_pm_gpio_num_parent} {
	detect_conn_pm_setting: detect_conn_pm_setting {
#if 0 && 0
		pins = SEC_GPIO(${det_pm_gpio_num_0}),
		       SEC_GPIO(${det_pm_gpio_num_1});
#elif 0
		pins = SEC_GPIO(${det_pm_gpio_num_0});
#elif 0
		pins = SEC_GPIO(${det_pm_gpio_num_1});
#endif
		function = "normal";
		power-source = <0>;
		bias-disable; /*NO PULL*/
		input-enable;
	};
};
#endif /*use_dynamic_pm_gpio_detect*/

#endif /* not CONFIG_SEC_FACTORY */

&smd {
	sec_abc {
		compatible = "samsung,sec_abc";
		status = "okay";

		gpu {
			gpu,label="GPU fault";
#if 0
			gpu,threshold_count=<4>;
			gpu,threshold_time=<1200>;
#else
			gpu,threshold_count=<20>;
			gpu,threshold_time=<1200>;
#endif
		};
#if 0
		gpu_page {
			gpu_page,label="GPU page fault";
			gpu_page,threshold_count=<20>;
			gpu_page,threshold_time=<1200>;
		};
#endif
		aicl {
			aicl,label="battery aicl";
			aicl,threshold_count=<5>;
			aicl,threshold_time=<300>;
		};
#if 0
		mipi_overflow {
			mipi_overflow,label="MIPI Overflow";
			mipi_overflow,threshold_count=<${mipi_overflow_threshold_count}>;
			mipi_overflow,threshold_time=<${mipi_overflow_threshold_time}>;
		};
#endif
#if 0
		motto {
			motto,label="motto info base";
			motto,info_bootcheck_base = <0x15860858>;
			motto,info_device_base = <0x1586085C>;
		};
#endif
	};
	abc_hub {
		compatible = "samsung,abc_hub";
		status = "okay";

#ifndef CONFIG_SEC_FACTORY
#if 0
#if 0 && 0
		pinctrl-names = "det_ap_connect","det_pm_connect";
		pinctrl-0 = <&detect_conn_setting>;
		pinctrl-1 = <&detect_conn_pm_setting>;
#elif 0
		pinctrl-names = "det_ap_connect";
		pinctrl-0 = <&detect_conn_setting>;
#elif 0
		pinctrl-names = "det_pm_connect";
		pinctrl-0 = <&detect_conn_pm_setting>;
#endif
/*not feature_abc_qcom_dt*/
#elif 0 && 0 && 0
		pinctrl-0 = <&sub_detect_conn_setting &sub_detect_conn_setting2 &cam_detect_conn_setting>;
#elif 0 && 0
		pinctrl-0 = <&sub_detect_conn_setting &cam_detect_conn_setting>;
#elif 0 && 0
		pinctrl-0 = <&sub_detect_conn_setting &sub_detect_conn_setting2>;
#elif 0
		pinctrl-0 = <&sub_detect_conn_setting>;
#elif 0
		pinctrl-0 = <&cam_detect_conn_setting>;
#endif
#endif /* not CONFIG_SEC_FACTORY */
		bootc {
			bootc,time_spec_user = <100000>; /* user binary user build */
			bootc,time_spec_eng = <100000>; /* user binary eng build */
			bootc,time_spec_fac = <100000>; /* factory binary */
		};

#ifndef CONFIG_SEC_FACTORY
#if 0
#if 0 || 0
		cond {
#if 0
			sec,det_conn_gpios = <
#if 0
					SEC_GPIO_REF(${det_gpio_num_0}) 0
#endif
#if 0
					SEC_GPIO_REF(${det_gpio_num_1}) 0
#endif
#if 0
					SEC_GPIO_REF(${det_gpio_num_2}) 0
#endif
#if 0
					SEC_GPIO_REF(${det_gpio_num_3}) 0
#endif
#if 0
					SEC_GPIO_REF(${det_gpio_num_4}) 0
#endif
#if 0
					SEC_GPIO_REF(${det_gpio_num_5}) 0
#endif
#if 0
					SEC_GPIO_REF(${det_gpio_num_6}) 0
#endif
#if 0
					SEC_GPIO_REF(${det_gpio_num_7}) 0
#endif
					>;
#if 0 || 0
			sec,det_conn_name =
#endif
#if 0 && 0
					"", "", "", "", "", "",
					"", "";
#elif 0
					"", "", "", "", "", "";
#elif 0
					"", "";
#endif
#endif /*use_dynamic_ap_gpio_detect*/

#if 0
			sec,det_pm_conn_gpios = <
#if 0
					SEC_GPIO_REF(${det_pm_gpio_num_0}) 0
#endif
#if 0
					SEC_GPIO_REF(${det_pm_gpio_num_1}) 0
#endif
					>;
#if 0 || 0
			sec,det_pm_conn_name =
#endif
#if 0 && 0
					"",
					"";
#elif 0
					"";
#elif 0
					"";
#endif
#endif /*use_dynamic_pm_gpio_detect */
		};
#endif /*use_dynamic_ap_gpio_detect || use_dynamic_pm_gpio_detect*/

/*not feature_abc_qcom_dt, feature_abc_lsi_dt*/
#elif 0 && 0 && 0
		cond {
			sec,det_conn_gpios = <SEC_GPIO_REF(${gpio_sub_connect_conn}) 0
						SEC_GPIO_REF(${gpio_sub_connect_conn2}) 0
						SEC_GPIO_REF(${gpio_cam_connect_conn}) 0>;
			sec,det_conn_name = "sub", "sub2", "cam";
			sec,det_conn_irq_type = <3>; /* BOTH EDGE */
		};
#elif 0 && 0
		cond {
			sec,det_conn_gpios = <SEC_GPIO_REF(${gpio_sub_connect_conn}) 0
						SEC_GPIO_REF(${gpio_cam_connect_conn}) 0>;
			sec,det_conn_name = "sub", "cam";
			sec,det_conn_irq_type = <3>; /* BOTH EDGE */
		};
#elif 0 && 0
		cond {
			sec,det_conn_gpios = <SEC_GPIO_REF(${gpio_sub_connect_conn}) 0
						SEC_GPIO_REF(${gpio_sub_connect_conn2}) 0>;
			sec,det_conn_name = "sub", "sub2";
			sec,det_conn_irq_type = <3>; /* BOTH EDGE */
		};
#elif 0
		cond {
			sec,det_conn_gpios = <SEC_GPIO_REF(${gpio_sub_connect_conn}) 0>;
			sec,det_conn_name = "sub";
			sec,det_conn_irq_type = <3>; /* BOTH EDGE */
		};
#elif 0
		cond {
			sec,det_conn_gpios = <SEC_GPIO_REF(${gpio_cam_connect_conn}) 0>;
			sec,det_conn_name = "cam";
			sec,det_conn_irq_type = <3>; /* BOTH EDGE */
		};
#endif
#endif /* not CONFIG_SEC_FACTORY */
	};
};

/* #include "../ap_mtk_mt6853.dtsi" */               /* From ap_mtk_mt6853.py */
#include <dt-bindings/clock/mt6853-clk.h>
#include "../../mediatek/k6853v1_64_titan.dts"


/* #include "../gpio_sec_detect_conn.dtsi" */        /* From gpio_sec_detect_conn.py */
#ifdef CONFIG_SEC_FACTORY
#if 1
&pio {
	detect_conn_setting: detect_conn_setting {
		config {
#if 0
			pinmux = <MTK_PINMUX(SEC_GPIO_NUM(AP,pio,69), 0)>,
			       <MTK_PINMUX(SEC_GPIO_NUM(${det_gpio_num_1}), 0)>,
			       <MTK_PINMUX(SEC_GPIO_NUM(${det_gpio_num_2}), 0)>,
			       <MTK_PINMUX(SEC_GPIO_NUM(${det_gpio_num_3}), 0)>,
			       <MTK_PINMUX(SEC_GPIO_NUM(${det_gpio_num_4}), 0)>,
#if 0
			       <MTK_PINMUX(SEC_GPIO_NUM(${det_gpio_num_5}), 0)>,
			       <MTK_PINMUX(SEC_GPIO_NUM(${det_gpio_num_6}), 0)>,
			       <MTK_PINMUX(SEC_GPIO_NUM(${det_gpio_num_7}), 0)>;
#elif 0
			       <MTK_PINMUX(SEC_GPIO_NUM(${det_gpio_num_5}), 0)>,
			       <MTK_PINMUX(SEC_GPIO_NUM(${det_gpio_num_6}), 0)>;
#else
			       <MTK_PINMUX(SEC_GPIO_NUM(${det_gpio_num_5}), 0)>;
#endif
#elif 0
			pinmux = <MTK_PINMUX(SEC_GPIO_NUM(AP,pio,69), 0)>,
			       <MTK_PINMUX(SEC_GPIO_NUM(${det_gpio_num_1}), 0)>,
			       <MTK_PINMUX(SEC_GPIO_NUM(${det_gpio_num_2}), 0)>,
			       <MTK_PINMUX(SEC_GPIO_NUM(${det_gpio_num_3}), 0)>,
#if 0
			       <MTK_PINMUX(SEC_GPIO_NUM(${det_gpio_num_4}), 0)>,
			       <MTK_PINMUX(SEC_GPIO_NUM(${det_gpio_num_6}), 0)>,
			       <MTK_PINMUX(SEC_GPIO_NUM(${det_gpio_num_7}), 0)>;
#elif 0
			       <MTK_PINMUX(SEC_GPIO_NUM(${det_gpio_num_4}), 0)>,
			       <MTK_PINMUX(SEC_GPIO_NUM(${det_gpio_num_6}), 0)>;
#else
			       <MTK_PINMUX(SEC_GPIO_NUM(${det_gpio_num_4}), 0)>;
#endif
#elif 0
			pinmux = <MTK_PINMUX(SEC_GPIO_NUM(AP,pio,69), 0)>,
			       <MTK_PINMUX(SEC_GPIO_NUM(${det_gpio_num_1}), 0)>,
			       <MTK_PINMUX(SEC_GPIO_NUM(${det_gpio_num_2}), 0)>,
#if 0
			       <MTK_PINMUX(SEC_GPIO_NUM(${det_gpio_num_3}), 0)>,
			       <MTK_PINMUX(SEC_GPIO_NUM(${det_gpio_num_6}), 0)>,
			       <MTK_PINMUX(SEC_GPIO_NUM(${det_gpio_num_7}), 0)>;
#elif 0
			       <MTK_PINMUX(SEC_GPIO_NUM(${det_gpio_num_3}), 0)>,
			       <MTK_PINMUX(SEC_GPIO_NUM(${det_gpio_num_6}), 0)>;
#else
			       <MTK_PINMUX(SEC_GPIO_NUM(${det_gpio_num_3}), 0)>;
#endif
#elif 0
			pinmux = <MTK_PINMUX(SEC_GPIO_NUM(AP,pio,69), 0)>,
			       <MTK_PINMUX(SEC_GPIO_NUM(${det_gpio_num_1}), 0)>,
#if 0
			       <MTK_PINMUX(SEC_GPIO_NUM(${det_gpio_num_2}), 0)>,
			       <MTK_PINMUX(SEC_GPIO_NUM(${det_gpio_num_6}), 0)>,
			       <MTK_PINMUX(SEC_GPIO_NUM(${det_gpio_num_7}), 0)>;
#elif 0
			       <MTK_PINMUX(SEC_GPIO_NUM(${det_gpio_num_2}), 0)>,
			       <MTK_PINMUX(SEC_GPIO_NUM(${det_gpio_num_6}), 0)>;
#else
			       <MTK_PINMUX(SEC_GPIO_NUM(${det_gpio_num_2}), 0)>;
#endif
#elif 0
			pinmux = <MTK_PINMUX(SEC_GPIO_NUM(AP,pio,69), 0)>,
#if 0
			       <MTK_PINMUX(SEC_GPIO_NUM(${det_gpio_num_1}), 0)>,
			       <MTK_PINMUX(SEC_GPIO_NUM(${det_gpio_num_6}), 0)>,
			       <MTK_PINMUX(SEC_GPIO_NUM(${det_gpio_num_7}), 0)>;
#elif 0
			       <MTK_PINMUX(SEC_GPIO_NUM(${det_gpio_num_1}), 0)>,
			       <MTK_PINMUX(SEC_GPIO_NUM(${det_gpio_num_6}), 0)>;
#else
			       <MTK_PINMUX(SEC_GPIO_NUM(${det_gpio_num_1}), 0)>;
#endif
#elif 1
			pinmux =
#if 0
			       <MTK_PINMUX(SEC_GPIO_NUM(AP,pio,69), 0)>,
			       <MTK_PINMUX(SEC_GPIO_NUM(${det_gpio_num_6}), 0)>,
			       <MTK_PINMUX(SEC_GPIO_NUM(${det_gpio_num_7}), 0)>;
#elif 0
			       <MTK_PINMUX(SEC_GPIO_NUM(AP,pio,69), 0)>,
			       <MTK_PINMUX(SEC_GPIO_NUM(${det_gpio_num_6}), 0)>;
#else
			       <MTK_PINMUX(SEC_GPIO_NUM(AP,pio,69), 0)>;
#endif
#elif 0
			pinmux = <MTK_PINMUX(SEC_GPIO_NUM(${det_gpio_num_6}), 0)>,
			       <MTK_PINMUX(SEC_GPIO_NUM(${det_gpio_num_7}), 0)>;
#elif 0
			pinmux = <MTK_PINMUX(SEC_GPIO_NUM(${det_gpio_num_6}), 0)>;
#endif
			drive-strength = <2>;
			bias-disable; /*NO PULL*/
			input-enable;
		};
	};
};
#endif /*use_dynamic_ap_gpio_detect*/

#if 0
&${det_pm_gpio_num_parent} {
	detect_conn_pm_setting: detect_conn_pm_setting {
#if 0 && 0
		pinmux = <MTK_PINMUX(SEC_GPIO_NUM(${det_pm_gpio_num_0}), 0)>,
		       <MTK_PINMUX(SEC_GPIO_NUM(${det_pm_gpio_num_1}), 0)>;
#elif 0
		pinmux = <MTK_PINMUX(SEC_GPIO_NUM(${det_pm_gpio_num_0}), 0)>;
#elif 0
		pinmux = <MTK_PINMUX(SEC_GPIO_NUM(${det_pm_gpio_num_1}), 0)>;
#endif
		function = "normal";
		power-source = <0>;
		bias-disable; /*NO PULL*/
		input-enable;
	};
};
#endif /*use_dynamic_pm_gpio_detect*/

&smd {
	sec_detect_conn {
		compatible = "samsung,sec_detect_conn";
		status = "okay";

#if 1
		sec,det_conn_gpios = <
#if 1
					SEC_GPIO_REF(AP,pio,69) 0
#endif
#if 0
					SEC_GPIO_REF(${det_gpio_num_1}) 0
#endif
#if 0
					SEC_GPIO_REF(${det_gpio_num_2}) 0
#endif
#if 0
					SEC_GPIO_REF(${det_gpio_num_3}) 0
#endif
#if 0
					SEC_GPIO_REF(${det_gpio_num_4}) 0
#endif
#if 0
					SEC_GPIO_REF(${det_gpio_num_5}) 0
#endif
#if 0
					SEC_GPIO_REF(${det_gpio_num_6}) 0
#endif
#if 0
					SEC_GPIO_REF(${det_gpio_num_7}) 0
#endif
					>;
#if 1 || 0
		sec,det_conn_name =
#endif
#if 1 && 0
					"SUB_CONNECT", "", "", "", "", "",
					"", "";
#elif 1
					"SUB_CONNECT", "", "", "", "", "";
#elif 0
					"", "";
#endif
#endif /*use_dynamic_ap_gpio_detect*/

#if 0
		sec,det_pm_conn_gpios = <
#if 0
					SEC_GPIO_REF(${det_pm_gpio_num_0}) 0
#endif
#if 0
					SEC_GPIO_REF(${det_pm_gpio_num_1}) 0
#endif
					>;
#if 0 || 0
		sec,det_pm_conn_name =
#endif
#if 0 && 0
					"",
					"";
#elif 0
					"";
#elif 0
					"";
#endif
#endif /*use_dynamic_pm_gpio_detect*/

#if 1 && 0
		pinctrl-names = "det_ap_connect","det_pm_connect";
		pinctrl-0 = <&detect_conn_setting>;
		pinctrl-1 = <&detect_conn_pm_setting>;
#elif 1
		pinctrl-names = "det_ap_connect";
		pinctrl-0 = <&detect_conn_setting>;
#elif 0
		pinctrl-names = "det_pm_connect";
		pinctrl-0 = <&detect_conn_pm_setting>;
#endif
	};
};
#endif /* CONFIG_SEC_FACTORY */


/* #include "../pmic_MT6359.dtsi" */                 /* From pmic_MT6359.py */
#if 0 && 0
&mt_pmic_vaud18_ldo_reg {
    regulator-min-microvolt = <0>;
    regulator-max-microvolt = <0>;
     
     
};
#endif

#if 0 && 0
&mt_pmic_vsim1_ldo_reg {
    regulator-min-microvolt = <0>;
    regulator-max-microvolt = <0>;
     
     
};
#endif

#if 3300000 && 3300000
&mt_pmic_vibr_ldo_reg {
    regulator-min-microvolt = <3300000>;
    regulator-max-microvolt = <3300000>;
     
     
};
#endif

#if 0 && 0
&mt_pmic_vrf12_ldo_reg {
    regulator-min-microvolt = <0>;
    regulator-max-microvolt = <0>;
     
     
};
#endif

#if 0 && 0
&mt_pmic_vusb_ldo_reg {
    regulator-min-microvolt = <0>;
    regulator-max-microvolt = <0>;
     
     
};
#endif

#if 0 && 0
&mt_pmic_vsram_proc2_ldo_reg {
    regulator-min-microvolt = <0>;
    regulator-max-microvolt = <0>;
     
     
};
#endif

#if 0 && 0
&mt_pmic_vio18_ldo_reg {
    regulator-min-microvolt = <0>;
    regulator-max-microvolt = <0>;
     
     
};
#endif

#if 0 && 0
&mt_pmic_vcamio_ldo_reg {
    regulator-min-microvolt = <0>;
    regulator-max-microvolt = <0>;
     
     
};
#endif

#if 0 && 0
&mt_pmic_vcn18_ldo_reg {
    regulator-min-microvolt = <0>;
    regulator-max-microvolt = <0>;
     
     
};
#endif

#if 0 && 0
&mt_pmic_vfe28_ldo_reg {
    regulator-min-microvolt = <0>;
    regulator-max-microvolt = <0>;
     
     
};
#endif

#if 0 && 0
&mt_pmic_vcn13_ldo_reg {
    regulator-min-microvolt = <0>;
    regulator-max-microvolt = <0>;
     
     
};
#endif

#if 0 && 0
&mt_pmic_vcn33_1_bt_ldo_reg {
    regulator-min-microvolt = <0>;
    regulator-max-microvolt = <0>;
     
     
};
#endif

#if 0 && 0
&mt_pmic_vcn33_1_wifi_ldo_reg {
    regulator-min-microvolt = <0>;
    regulator-max-microvolt = <0>;
     
     
};
#endif

#if 0 && 0
&mt_pmic_vaux18_ldo_reg {
    regulator-min-microvolt = <0>;
    regulator-max-microvolt = <0>;
     
     
};
#endif

#if 0 && 0
&mt_pmic_vsram_others_ldo_reg {
    regulator-min-microvolt = <0>;
    regulator-max-microvolt = <0>;
     
     
};
#endif

#if 0 && 0
&mt_pmic_vefuse_ldo_reg {
    regulator-min-microvolt = <0>;
    regulator-max-microvolt = <0>;
     
     
};
#endif

#if 0 && 0
&mt_pmic_vxo22_ldo_reg {
    regulator-min-microvolt = <0>;
    regulator-max-microvolt = <0>;
     
     
};
#endif

#if 0 && 0
&mt_pmic_vrfck_ldo_reg {
    regulator-min-microvolt = <0>;
    regulator-max-microvolt = <0>;
     
     
};
#endif

#if 0 && 0
&mt_pmic_vbif28_ldo_reg {
    regulator-min-microvolt = <0>;
    regulator-max-microvolt = <0>;
     
     
};
#endif

#if 3300000 && 3300000
&mt_pmic_vio28_ldo_reg {
    regulator-min-microvolt = <3300000>;
    regulator-max-microvolt = <3300000>;
     
     
};
#endif

#if 0 && 0
&mt_pmic_vemc_ldo_reg {
    regulator-min-microvolt = <0>;
    regulator-max-microvolt = <0>;
     
     
};
#endif

#if 0 && 0
&mt_pmic_vcn33_2_bt_ldo_reg {
    regulator-min-microvolt = <0>;
    regulator-max-microvolt = <0>;
     
     
};
#endif

#if 0 && 0
&mt_pmic_vcn33_2_wifi_ldo_reg {
    regulator-min-microvolt = <0>;
    regulator-max-microvolt = <0>;
     
     
};
#endif

#if 0 && 0
&mt_pmic_va12_ldo_reg {
    regulator-min-microvolt = <0>;
    regulator-max-microvolt = <0>;
     
     
};
#endif

#if 0 && 0
&mt_pmic_va09_ldo_reg {
    regulator-min-microvolt = <0>;
    regulator-max-microvolt = <0>;
     
     
};
#endif

#if 0 && 0
&mt_pmic_vrf18_ldo_reg {
    regulator-min-microvolt = <0>;
    regulator-max-microvolt = <0>;
     
     
};
#endif

#if 0 && 0
&mt_pmic_vsram_md_ldo_reg {
    regulator-min-microvolt = <0>;
    regulator-max-microvolt = <0>;
     
     
};
#endif

#if 0 && 0
&mt_pmic_vufs_ldo_reg {
    regulator-min-microvolt = <0>;
    regulator-max-microvolt = <0>;
     
     
};
#endif

#if 0 && 0
&mt_pmic_vm18_ldo_reg {
    regulator-min-microvolt = <0>;
    regulator-max-microvolt = <0>;
     
     
};
#endif

#if 0 && 0
&mt_pmic_vbbck_ldo_reg {
    regulator-min-microvolt = <0>;
    regulator-max-microvolt = <0>;
     
     
};
#endif

#if 0 && 0
&mt_pmic_vsram_proc1_ldo_reg {
    regulator-min-microvolt = <0>;
    regulator-max-microvolt = <0>;
     
     
};
#endif

#if 0 && 0
&mt_pmic_vsim2_ldo_reg {
    regulator-min-microvolt = <0>;
    regulator-max-microvolt = <0>;
     
     
};
#endif

/* #include "../hall_ic.dtsi" */                     /* From hall_ic.py */
/*
 * Hall ic device tree source
 *
 * Copyright (c) 2017 Samsung Electronics Co., Ltd.
 *		http://www.samsung.com
 *
 * This program is free software; you can redistribute it and/or modify
 * it under the terms of the GNU General Public License version 2 as
 * published by the Free Software Foundation.
 */

&smd {
	hall_ic {
		status = "okay";
		compatible = "hall_ic";
		pinctrl-names = "default";
		pinctrl-0 = <&hall_irq &certify_hall_irq>;
		hall {
			name = "hall";
			event = <0x15>;
			gpios = <SEC_GPIO_REF(AP,pio,76) 1>;
		};
		certify_hall {
			name = "certify_hall";
			event = <0x1b>;
			gpios = <SEC_GPIO_REF(AP,pio,11) 1>;
		};
	};
};

&pio {
	hall_irq: hall_irq {
		pinmux = <MTK_PINMUX(SEC_GPIO_NUM(AP,pio,76), 0)>;
		bias-disable;
	};
};

&pio {
	certify_hall_irq: certify_hall_irq {
		pinmux = <MTK_PINMUX(SEC_GPIO_NUM(AP,pio,11), 0)>;
		bias-disable;
	};
};

/* #include "../sec_thermistor.dtsi" */              /* From sec_thermistor.py */
/ {
	fragment@smd {
		target-path = "/";
		__overlay__ {
			samsung_mobile_device {
				sec_ap_thermistor: sec_thermistor@0 {
					compatible = "samsung,sec-thermistor";
					status = "okay";
					thermistor_name = "sec-ap-thermistor";
					id = <0>;

					io-channels = SEC_ADC(auxadc,0);
					io-channel-names = "ap_therm";
					io-channel-ranges;
				};
			};
		};
	};
};

/* #include "../sec_thermistor-2.dtsi" */            /* From sec_thermistor.py */
/ {
	fragment@smd {
		target-path = "/";
		__overlay__ {
			samsung_mobile_device {
				sec_cp_thermistor: sec_thermistor@2 {
					compatible = "samsung,sec-thermistor";
					status = "okay";
					thermistor_name = "sec-cp-thermistor";
					id = <2>;

					io-channels = SEC_ADC(auxadc,2);
					io-channel-names = "cp_therm";
					io-channel-ranges;
				};
			};
		};
	};
};

/* #include "../sec_thermistor-3.dtsi" */            /* From sec_thermistor.py */
/ {
	fragment@smd {
		target-path = "/";
		__overlay__ {
			samsung_mobile_device {
				sec_wf_thermistor: sec_thermistor@3 {
					compatible = "samsung,sec-thermistor";
					status = "okay";
					thermistor_name = "sec-wf-thermistor";
					id = <3>;

					io-channels = SEC_ADC(auxadc,4);
					io-channel-names = "wf_therm";
					io-channel-ranges;
				};
			};
		};
	};
};

/* #include "../sec_thermistor-1.dtsi" */            /* From sec_thermistor.py */
/ {
	fragment@smd {
		target-path = "/";
		__overlay__ {
			samsung_mobile_device {
				sec_pa_thermistor: sec_thermistor@1 {
					compatible = "samsung,sec-thermistor";
					status = "okay";
					thermistor_name = "sec-pa-thermistor";
					id = <1>;

					io-channels = SEC_ADC(auxadc,1);
					io-channel-names = "pa_therm";
					io-channel-ranges;
				};
			};
		};
	};
};

/* /home/dpi/qb5_8815/workspace/P4_1716/android/kernel/kmodule/hwmon/sec_thermistor/sec_thermistor_mtk.a32x.dtsi */
&sec_ap_thermistor {
	use_iio_processed;
	adc_array = <108 124 177 209 254 308 373 442 525 590
				652 758 855 912 1092 1318 1556 1824 1929 2130
				2323 2458 2795 3088 3320>;

	temp_array = <850 800 700 650 600 550 500 450 400 370
				350 300 270 250 200 150 100 50 30 0
				(-30) (-50) (-100) (-150) (-200)>;
};

&sec_pa_thermistor {
	use_iio_processed;
	adc_array = <394 475 652 758 896 1050 1226 1402 1600 1744
				1874 2089 2260 2356 2633 2934 3202 3461 3558 3712
				3853 3940>;

	temp_array = <850 800 700 650 600 550 500 450 400 370
				350 300 270 250 200 150 100 50 30 0
				(-30) (-50)>;
};

&sec_cp_thermistor {
	use_iio_processed;
	adc_array = <382 475 652 757 895 1049 1224 1402 1595 1741
				1868 2084 2255 2352 2629 2930 3199 3456 3550 3710
				3849 3939>;

	temp_array = <850 800 700 650 600 550 500 450 400 370
				350 300 270 250 200 150 100 50 30 0
				(-30) (-50)>;
};

&sec_wf_thermistor {
	use_iio_processed;
	adc_array = <393 475 650 758 885 1050 1226 1399 1597 1740
				1865 2074 2239 2341 2619 2885 3186 3446 3558 3703
				3837 3936>;

	temp_array = <850 800 700 650 600 550 500 450 400 370
				350 300 270 250 200 150 100 50 30 0
				(-30) (-50)>;
};

/* #include "../pmic_MT6360.dtsi" */                 /* From pmic_MT6360.py */
#if 1800000 && 1800000
&mt_pmic_vfp_ldo_reg {
    regulator-min-microvolt = <1800000>;
    regulator-max-microvolt = <1800000>;
     
     
};
#endif

#if 1800000 && 1800000
&mt_pmic_vtp_ldo_reg {
    regulator-min-microvolt = <1800000>;
    regulator-max-microvolt = <1800000>;
     regulator-always-on;
     
};
#endif

#if 0 && 0
&mt_pmic_vmc_ldo_reg {
    regulator-min-microvolt = <0>;
    regulator-max-microvolt = <0>;
     
     
};
#endif

#if 0 && 0
&mt_pmic_vmch_ldo_reg {
    regulator-min-microvolt = <0>;
    regulator-max-microvolt = <0>;
     
     
};
#endif
/* #include "../battery_common.dtsi" */              /* From battery_common.py */
#include <dt-bindings/battery/sec-battery.h>

&smd {
	sec_battery: battery {
		status = "okay";
		compatible = "samsung,sec-battery";
		battery,vendor = "Battery";
		battery,charger_name = "mtk-charger";
		battery,technology = <2>; /* POWER_SUPPLY_TECHNOLOGY_LION */

		battery,batt_data_version = <1>;

		battery,temp_adc_type = <SEC_BATTERY_ADC_TYPE_AP>; /* SEC_BATTERY_ADC_TYPE_AP */
		battery,adc_check_count = <5>;
		battery,temp_check_type = <SEC_BATTERY_TEMP_CHECK_NONE>;
		battery,usb_temp_check_type = <SEC_BATTERY_TEMP_CHECK_NONE>;
		battery,chg_temp_check_type = <SEC_BATTERY_TEMP_CHECK_NONE>;
		battery,wpc_temp_check_type = <SEC_BATTERY_TEMP_CHECK_NONE>;

		battery,thermal_source = <SEC_BATTERY_THERMAL_SOURCE_NONE>; /* SEC_BATTERY_THERMAL_SOURCE_NONE */
		battery,usb_thermal_source = <SEC_BATTERY_THERMAL_SOURCE_NONE>; /* SEC_BATTERY_THERMAL_SOURCE_NONE */
		battery,chg_thermal_source = <SEC_BATTERY_THERMAL_SOURCE_NONE>; /* SEC_BATTERY_THERMAL_SOURCE_NONE */
		battery,wpc_thermal_source = <SEC_BATTERY_THERMAL_SOURCE_NONE>; /* SEC_BATTERY_THERMAL_SOURCE_NONE */

		battery,polling_time = <10 30 30 30 3600>;

		battery,cable_check_type = <4>; /* SEC_BATTERY_CABLE_CHECK_PSY */
		battery,cable_source_type = <SEC_BATTERY_CABLE_SOURCE_EXTERNAL>;
		battery,polling_type = <SEC_BATTERY_MONITOR_ALARM>; /* SEC_BATTERY_MONITOR_ALARM */
		battery,monitor_initial_count = <0>;

		battery,battery_check_type = <0>; /* SEC_BATTERY_CHECK_NONE */

		battery,ovp_uvlo_check_type = <SEC_BATTERY_OVP_UVLO_CHGPOLLING>; /* SEC_BATTERY_OVP_UVLO_CHGPOLLING */

		battery,temp_check_count = <1>;
		battery,temp_highlimit_threshold_event = <800>;
		battery,temp_highlimit_recovery_event = <780>;
		battery,temp_high_threshold_event = <500>;
		battery,temp_high_recovery_event = <480>;
		battery,temp_low_threshold_event = <0>;
		battery,temp_low_recovery_event = <20>;
		battery,temp_highlimit_threshold_normal = <800>;
		battery,temp_highlimit_recovery_normal = <780>;
		battery,temp_high_threshold_normal = <500>;
		battery,temp_high_recovery_normal = <480>;
		battery,temp_low_threshold_normal = <0>;
		battery,temp_low_recovery_normal = <20>;
		battery,temp_highlimit_threshold_lpm = <800>;
		battery,temp_highlimit_recovery_lpm = <780>;
		battery,temp_high_threshold_lpm = <500>;
		battery,temp_high_recovery_lpm = <480>;
		battery,temp_low_threshold_lpm = <0>;
		battery,temp_low_recovery_lpm = <20>;
		battery,wpc_high_threshold_normal = <450>;
		battery,wpc_high_recovery_normal = <430>;
		battery,wpc_low_threshold_normal = <0>;
		battery,wpc_low_recovery_normal = <20>;
		battery,full_check_type = <SEC_BATTERY_FULLCHARGED_CHGPSY>;
		battery,full_check_type_2nd = <SEC_BATTERY_FULLCHARGED_CHGPSY>;
		battery,full_check_count = <1>;
		battery,chg_gpio_full_check = <0>;
		battery,chg_polarity_full_check = <1>;

		battery,chg_high_temp = <460>;
		battery,chg_high_temp_recovery = <440>;
		battery,chg_input_limit_current = <1000>;
		battery,chg_charging_limit_current = <1400>;

		battery,wpc_temp_control_source = <TEMP_CONTROL_SOURCE_BAT_THM>;
		battery,wpc_high_temp = <380>;
		battery,wpc_high_temp_recovery = <360>;
		battery,wpc_input_limit_current = <600>;
		battery,wpc_charging_limit_current = <1000>;
		battery,wpc_temp_lcd_on_control_source = <TEMP_CONTROL_SOURCE_BAT_THM>;
		battery,wpc_lcd_on_high_temp = <380>;
		battery,wpc_lcd_on_high_temp_rec = <360>;
		battery,wpc_lcd_on_input_limit_current = <450>;

		battery,wpc_store_high_temp = <360>;
		battery,wpc_store_high_temp_recovery = <340>;
		battery,wpc_store_charging_limit_current = <400>;
		battery,wpc_store_lcd_on_high_temp = <360>;
		battery,wpc_store_lcd_on_high_temp_rec = <300>;
		battery,wpc_store_lcd_on_charging_limit_current = <400>;

		battery,sleep_mode_limit_current = <500>;
		battery,wc_full_input_limit_current = <100>;

		battery,mix_high_temp = <420>;
		battery,mix_high_chg_temp = <500>;
		battery,mix_high_temp_recovery = <390>;

		battery,full_condition_type = <(SEC_BATTERY_FULL_CONDITION_NOTIMEFULL | SEC_BATTERY_FULL_CONDITION_VCELL)>;
		battery,full_condition_soc = <93>;
		battery,full_condition_vcell = <4250>;

		battery,recharge_check_count = <1>;
		battery,recharge_condition_type = <SEC_BATTERY_RECHARGE_CONDITION_VCELL>;
		battery,recharge_condition_soc = <98>;
		battery,recharge_condition_vcell = <4280>;

		battery,charging_total_time = <14400>;
		battery,hv_charging_total_time = <10800>;
		battery,normal_charging_total_time = <18000>;
		battery,usb_charging_total_time = <36000>;
		battery,recharging_total_time = <5400>;
		battery,charging_reset_time = <0>;

		battery,chg_float_voltage = <4350>;

		battery,pre_afc_work_delay = <2000>;
		battery,pre_wc_afc_work_delay = <4000>;
		battery,pre_afc_input_current = <500>;
		battery,pre_wc_afc_input_current = <500>;
		battery,prepare_ta_delay = <0>; /* msec */

		battery,swelling_high_temp_block = <410>;
		battery,swelling_high_temp_recov = <390>;
		battery,swelling_low_temp_block_1st = <150>;
		battery,swelling_low_temp_recov_1st = <170>;
		battery,swelling_low_temp_block_2nd = <50>;
		battery,swelling_low_temp_recov_2nd = <70>;

		battery,swelling_drop_float_voltage = <4150>;
		battery,swelling_high_rechg_voltage = <4000>;
		battery,swelling_low_rechg_voltage = <4000>;

		battery,siop_input_limit_current = <1200>;
		battery,siop_charging_limit_current = <1000>;
		battery,siop_hv_input_limit_current = <700>;
		battery,siop_hv_input_limit_current_2nd = <550>;
		battery,siop_hv_charging_limit_current = <1000>;

		battery,rp_current_rp1 = <500>;
		battery,rp_current_rp2 = <1500>;
		battery,rp_current_rp3 = <3000>;
		battery,rp_current_rdu_rp3 = <2100>;
		battery,rp_current_abnormal_rp3 = <1800>;

		battery,pd_charging_charge_power = <15000>;
		battery,max_charging_current = <2350>;

		battery,wireless_cc_cv = <85>;
		battery,wireless_otg_input_current = <900>;

		/* cycle, chg_float_voltage, recharge_condition_vcell, full_condition_vcell, full_condition_soc, step charging condition */
		battery,age_data = <0 4350 4280 4250 93
			300 4330 4260 4230 92
			400 4310 4240 4210 91
			700 4290 4220 4190 90
			1000 4240 4170 4140 89>;

		battery,max_input_voltage = <9000>; /* mV */
		battery,max_input_current = <3000>;  /* mA */

		battery,cisd_alg_index = <8>;
		battery,cisd_max_voltage_thr = <4400>; /* batttery ovp dettection voltage */
		battery,ignore_cisd_index = <0 960>; /* Do not use AFC_FAIL to DROP_VALUE */
		battery,ignore_cisd_index_d = <0 120>; /* Do not use AFC_FAIL_PER_DAY to DROP_VALUE_PER_DAY */

		battery,expired_time = <10800>;
		battery,recharging_expired_time = <5400>;

		battery,battery_full_capacity = <3300>;

		io-channels = <&auxadc 3>;
		io-channel-names = "adc-chg-temp", "n/a", "n/a", "n/a", "n/a";
	};

	/* sec_battery_cable
	 *   0	UNKNOWN,
	 *   1	NONE,
	 *   2	PREPARE_TA,
	 *   3	TA,
	 *   4	USB,
	 *   5	USB_CDP,
	 *   6	9V_TA,
	 *   7	9V_ERR,
	 *   8	9V_UNKNOWN,
	 *   9	12V_TA,
	 *  10	WIRELESS,
	 *  11	HV_WIRELESS,
	 *  12	PMA_WIRELESS,
	 *  13	WIRELESS_PACK,
	 *  14	CABLE_WIRELESS_HV_PACK,
	 *  15	WIRELESS_STAND,
	 *  16	WIRELESS_HV_STAND,
	 *  17	QC20,
	 *  18	QC30,
	 *  19	PDIC,
	 *  20	UARTOFF,
	 *  21	OTG,
	 *  22	LAN_HUB,
	 *  23	POWER_SHARING,
	 *  24	HMT_CONNECTED,
	 *  25	HMT_CHARGE,
	 *  26	HV_TA_CHG_LIMIT,
	 *  27	WIRELESS_VEHICLE,
	 *  28	WIRELESS_HV_VEHICLE,
	 *  29	PREPARE_WIRELESS_HV,
	 *  30  TIMEOUT,
	 *  31  SMART_OTG,
	 *  32  SMART_NOTG,
	 *  33  WIRELESS_TX,
	 *  34	HV_WIRELESS_20,
	 *  35	HV_WIRELESS_20_LIMIT,
	 *  36	WIRELESS_FAKE,
	 *  37  PREPARE_WIRELESS_20,
	 *  38	CABLE_PDIC_APDO,
	 *  39	CABLE_MAX,
	 */
	sec_battery_cable: cable-info {
		default_input_current = <1800>;
		default_charging_current = <2100>;
		full_check_current_1st = <350>;
		full_check_current_2nd = <200>;

		current_group_1 {
			cable_number = <
				SEC_BATTERY_CABLE_PREPARE_TA
				SEC_BATTERY_CABLE_PDIC
				SEC_BATTERY_CABLE_OTG
				SEC_BATTERY_CABLE_LAN_HUB
				SEC_BATTERY_CABLE_POWER_SHARING>;
			input_current = <500>;
			charging_current = <500>;
		};
		current_group_2 {
			cable_number = <
				SEC_BATTERY_CABLE_HMT_CHARGE
				SEC_BATTERY_CABLE_SMART_OTG>;
			input_current = <1000>;
			charging_current = <1000>;
		};
		current_group_3 {
			cable_number = <
				SEC_BATTERY_CABLE_USB_CDP
				SEC_BATTERY_CABLE_SMART_NOTG>;
			input_current = <1500>;
			charging_current = <1500>;
		};
		current_group_4 {
			cable_number = <SEC_BATTERY_CABLE_9V_TA SEC_BATTERY_CABLE_9V_ERR
				SEC_BATTERY_CABLE_9V_UNKNOWN SEC_BATTERY_CABLE_QC20
				SEC_BATTERY_CABLE_QC30 SEC_BATTERY_CABLE_9V_POGO>;
			input_current = <1650>;
			charging_current = <2350>;
		};
		current_group_5 {
			cable_number = <SEC_BATTERY_CABLE_12V_TA>;
			input_current = <1650>;
			charging_current = <2350>;
		};
		current_group_6 {
			cable_number = <
				SEC_BATTERY_CABLE_WIRELESS
				SEC_BATTERY_CABLE_PMA_WIRELESS
				SEC_BATTERY_CABLE_WIRELESS_STAND
				SEC_BATTERY_CABLE_WIRELESS_VEHICLE
				SEC_BATTERY_CABLE_WIRELESS_TX
				SEC_BATTERY_CABLE_WIRELESS_FAKE>;
			input_current = <800>;
			charging_current = <2350>;
		};
		current_group_7 {
			cable_number = <SEC_BATTERY_CABLE_WIRELESS_PACK>;
			input_current = <700>;
			charging_current = <2350>;
		};
		current_group_8 {
			cable_number = <SEC_BATTERY_CABLE_HMT_CONNECTED>;
			input_current = <1000>;
			charging_current = <450>;
		};
		current_group_9 {
			cable_number = <SEC_BATTERY_CABLE_HV_TA_CHG_LIMIT>;
			input_current = <1800>;
			charging_current = <1800>;
		};
		current_group_10 {
			cable_number = <
				SEC_BATTERY_CABLE_HV_WIRELESS
				SEC_BATTERY_CABLE_WIRELESS_HV_PACK
				SEC_BATTERY_CABLE_WIRELESS_HV_STAND
				SEC_BATTERY_CABLE_WIRELESS_HV_VEHICLE
				SEC_BATTERY_CABLE_HV_WIRELESS_20_LIMIT>;
			input_current = <650>;
			charging_current = <2350>;
		};
		current_group_11 {
			cable_number = <
				SEC_BATTERY_CABLE_PREPARE_WIRELESS_HV
				SEC_BATTERY_CABLE_PREPARE_WIRELESS_20>;
			input_current = <500>;
			charging_current = <1200>;
		};
		current_group_12 {
			cable_number = <
				SEC_BATTERY_CABLE_NONE
				SEC_BATTERY_CABLE_USB
				SEC_BATTERY_CABLE_TIMEOUT>;
			input_current = <475>;
			charging_current = <550>;
		};
		current_group_13 {
			cable_number = <SEC_BATTERY_CABLE_HV_WIRELESS_20>;
			input_current = <1200>;
			charging_current = <2350>;
		};
	};
};

/* /home/dpi/qb5_8815/workspace/P4_1716/android/kernel/kmodule/battery/common/dts/battery_common.a32x.dtsi */
&sec_battery {
		pinctrl-names = "default";

		battery,chip_vendor = "MTK";

		battery,temp_check_type = <SEC_BATTERY_TEMP_CHECK_ADC>;
		battery,chg_temp_check_type = <SEC_BATTERY_TEMP_CHECK_ADC>;

		battery,thermal_source = <SEC_BATTERY_THERMAL_SOURCE_FG_ADC>;
		battery,chg_thermal_source = <SEC_BATTERY_THERMAL_SOURCE_ADC>;

		battery,temp_table_adc = <
					209 259 307 411 472 539 612 718 824 959 1044
					1116 1247 1338 1398 1552 1726 1872 2014 2071 2161
					2233 2286 2398 2480 2532
					>;
		battery,temp_table_data = <
					900 850 800 700 650 600 550 500 450 400 370
					350 300 270 250 200 150 100 50 30 0
					(-30) (-50) (-100) (-150) (-200)
					>;

		battery,chg_temp_table_adc = <
					340 405 474 651 757 886 1020 1200 1389 1606 1748
					1880 2090 2264 2358 2636 2938 3206 3464 3561 3716
					3858 3941 4122 4122 4122
					>;
		battery,chg_temp_table_data = <
					900 850 800 700 650 600 550 500 450 400 370
					350 300 270 250 200 150 100 50 30 0
					(-30) (-50) (-100) (-150) (-200)
					>;

		battery,temp_check_count = <1>;
		battery,overheatlimit_threshold = <700>;
		battery,overheatlimit_recovery = <680>;

		battery,wire_warm_overheat_thresh = <500>;
		battery,wire_normal_warm_thresh = <420>;
		battery,wire_cool1_normal_thresh = <180>;
		battery,wire_cool2_cool1_thresh = <150>;
		battery,wire_cool3_cool2_thresh = <50>;
		battery,wire_cold_cool3_thresh = <0>;

		battery,wire_warm_current = <1750>;	/* 0.36C */
		battery,wire_cool1_current = <2400>; /* 0.72C */
		battery,wire_cool2_current = <1150>;	/* 0.24C */
		battery,wire_cool3_current = <500>;	/* 0.1C */

		battery,high_temp_topoff = <250>;
		battery,low_temp_topoff = <250>;
		battery,high_temp_float = <4150>;
		battery,low_temp_float = <4380>;

		battery,chg_high_temp = <500>;
		battery,chg_high_temp_recovery = <480>;

		battery,full_check_type = <SEC_BATTERY_FULLCHARGED_FG_CURRENT>;
		battery,full_check_type_2nd = <SEC_BATTERY_FULLCHARGED_FG_CURRENT>;

		battery,full_condition_vcell = <4280>;
		battery,recharge_condition_vcell = <4310>;
		battery,chg_float_voltage = <4380>;

		battery,swelling_high_rechg_voltage = <4000>;
		battery,swelling_low_rechg_voltage = <4230>;

		battery,siop_apdo_input_limit_current = <1200>;
		battery,siop_apdo_charging_limit_current = <2000>;

		battery,max_charging_current = <2400>;
		battery,max_charging_charge_power = <15000>; /* 15W */

		/* cycle, chg_float_voltage, recharge_condition_vcell, full_condition_vcell, full_condition_soc, step charging condition */
		battery,age_data = <0 4380 4310 4280 93
			300 4360 4290 4260 92
			400 4340 4270 4240 91
			700 4320 4250 4220 90
			1000 4270 4200 4170 89>;

		battery,health_condition = <
			/* CYCLE ASOC */
			900 0  /* GOOD */
			1200 0 /* NORMAL */
			1500 0 /* AGED */
			>;

		battery,standard_curr = <2400>;
		battery,expired_time = <13800>; /* 160 + 70 minutes */
		battery,recharging_expired_time = <5400>;
		battery,battery_full_capacity = <5000>;
		battery,cisd_max_voltage_thr = <5000>; /* batttery ovp dettection voltage */

		battery,volt_from_pmic;

		battery,ttf_hv_charge_current = <2220>;
		battery,ttf_capacity = <4930>;
		battery,cv_data = <
					2337	727	2284
					2336	732	2260
					2297	743	2180
					2227	754	2100
					2157	759	2054
					2110	765	2019
					2056	770	1979
					1979	775	1918
					1900	785	1859
					1772	798	1755
					1676	810	1668
					1612	815	1609
					1509	827	1509
					1396	837	1408
					1281	848	1309
					1163	859	1188
					1109	864	1128
					1055	870	1068
					956		881	938
					851		892	793
					811		897	728
					765		897	613
					617		914	323
					579		919	234
					541		924	138
					538		924	127
					526		930	94
					512		930	60
					500		930	28
					493		935	8
					493		935	0
					>;
};

&sec_battery_cable {
		full_check_current_1st = <500>;
		full_check_current_2nd = <250>;

		current_group_4 {
			charging_current = <2400>;
		};
		current_group_5 {
			charging_current = <2400>;
		};
		current_group_6 {
			charging_current = <2400>;
		};
		current_group_7 {
			charging_current = <2400>;
		};
		current_group_10 {
			charging_current = <2400>;
		};
};

/* #include "../dc_vibrator.dtsi" */                 /* From dc_vibrator.py */
/ {
	fragment@smd {
		target-path = "/";
			__overlay__ {
				samsung_mobile_device {
					dc_vibrator {
						compatible = "samsung,dc_vibrator";
						status = "okay";
						dc_vib,motor_type = "COINDC";
						dc_vib,regulator_name = "vibr";
					};
				};
			};
	};
};

/* #include "../fingerprint_et5xx.dtsi" */           /* From fingerprint_et5xx.py */
/*
 * Copyright (c) 2012-2013, The Linux Foundation. All rights reserved.
 *
 * This program is free software; you can redistribute it and/or modify
 * it under the terms of the GNU General Public License version 2 and
 * only version 2 as published by the Free Software Foundation.
 *
 * This program is distributed in the hope that it will be useful,
 * but WITHOUT ANY WARRANTY; without even the implied warranty of
 * MERCHANTABILITY or FITNESS FOR A PARTICULAR PURPOSE.  See the
 * GNU General Public License for more details.
 */

/* drive-strength */
&pio {
	btp_irq: btp-irq {
		pins_cmd_dat{
			pinmux = <MTK_PINMUX(SEC_GPIO_NUM(AP,pio,15), 0)>;
			bias-pull-down;
			drive-strength = <1>;
		};
	};
	btp_irq_sleep: btp-irq-sleep {
		pins_cmd_dat{
			pinmux = <MTK_PINMUX(SEC_GPIO_NUM(AP,pio,15), 0)>;
			bias-pull-down;
			input-enable;
			drive-strength = <1>;
		};
	};
};

&pio {
	btp_sleep: btp_sleep_enable {
		pins_cmd_dat{
			pinmux = <MTK_PINMUX(SEC_GPIO_NUM(AP,pio,41), 0)>;
			bias-pull-down;
			drive-strength = <1>;
		};
	};
};

&pio {
	spi5_set_miso: set_miso {
		pins_cmd_dat{
			pinmux = <MTK_PINMUX(SEC_GPIO_NUM(AP,pio,31), 1)>;
			drive-strength = <4>;
		};
	};
	spi5_set_cs: set_cs {
		pins_cmd_dat{
			pinmux = <MTK_PINMUX(SEC_GPIO_NUM(AP,pio,29), 1)>;
			drive-strength = <4>;
		};
	};
	spi5_set_mosi: set_mosi {
		pins_cmd_dat{
			pinmux = <MTK_PINMUX(SEC_GPIO_NUM(AP,pio,30), 1)>;
			drive-strength = <4>;
		};
	};
	spi5_set_clk: set_clk {
		pins_cmd_dat{
			pinmux = <MTK_PINMUX(SEC_GPIO_NUM(AP,pio,28), 1)>;
			drive-strength = <4>;
		};
	};
	spi5_clr_miso: clr_miso {
		pins_cmd_dat{
			pinmux = <MTK_PINMUX(SEC_GPIO_NUM(AP,pio,31), 0)>;
			slew-rate = <0>;
			bias-pull-down;
			input-enable;
			drive-strength = <1>;
		};
	};
	spi5_clr_cs: clr_cs {
		pins_cmd_dat{
			pinmux = <MTK_PINMUX(SEC_GPIO_NUM(AP,pio,29), 0)>;
			slew-rate = <0>;
			bias-pull-down;
			output-low;
			drive-strength = <1>;
		};
	};
	spi5_clr_mosi: clr_mosi {
		pins_cmd_dat{
			pinmux = <MTK_PINMUX(SEC_GPIO_NUM(AP,pio,30), 0)>;
			slew-rate = <0>;
			bias-pull-down;
			output-low;
			drive-strength = <1>;
		};
	};
	spi5_clr_clk: clr_clk {
		pins_cmd_dat{
			pinmux = <MTK_PINMUX(SEC_GPIO_NUM(AP,pio,28), 0)>;
			slew-rate = <0>;
			bias-pull-down;
			output-low;
			drive-strength = <1>;
		};
	};
};

&mt_pmic_vio28_ldo_reg {
    regulator-name = "VDD_BTP_3P3";
    regulator-min-microvolt = <3300000>;
    regulator-max-microvolt = <3300000>;
};

#if defined(CONFIG_SEC_FACTORY) || !1
&spi5 {
	status = "okay";
#else
&smd {
#endif
	#address-cells = <1>;
	#size-cells = <0>;

	etspi-spi@0 {
		compatible = "etspi,et5xx";
		reg = <0x00>;
		spi-max-frequency = <25000000>;
#if !defined(CONFIG_SEC_FACTORY) && 1
		clocks = <&topckgen_clk CLK_TOP_MAINPLL_D5_D4>,
			<&topckgen_clk CLK_TOP_SPI_SEL>,
			<&infracfg_ao_clk CLK_IFRAO_SPI5>;
		clock-names = "parent-clk", "sel-clk", "spi-clk";
#endif
		pinctrl-names = "default", "pins_poweron", "pins_poweroff", "pins_poweron_tz", "pins_poweroff_tz";
		pinctrl-0 = <&btp_sleep &btp_irq>;
		pinctrl-1 = <&spi5_set_miso &spi5_set_cs &spi5_set_mosi &spi5_set_clk>;
		pinctrl-2 = <&btp_sleep &spi5_clr_miso &spi5_clr_cs &spi5_clr_mosi &spi5_clr_clk>;
		pinctrl-3 = <&btp_irq>;
		pinctrl-4 = <&btp_irq_sleep>;
		gpio-controller;
		#gpio-cells = <2>;
#if 0
		etspi-ldoPin = <SEC_GPIO_REF(${fps_ldo_vdd_3p3}) 0>;
#endif
#if 1
		etspi-regulator = "VDD_BTP_3P3";
#endif
		etspi-sleepPin = <SEC_GPIO_REF(AP,pio,41) 0>;
		etspi-drdyPin = <SEC_GPIO_REF(AP,pio,15) 0>;
		etspi-chipid = "ET523";
		etspi-orient = <2>;
		controller-data {
			mediatek,tckdly = <1>;	/* It'll be used after tckdly patch */
		};
	};
};

/* #include "../nfc_lsi.dtsi" */                     /* From nfc_lsi.py */
/*
 * This program is free software; you can redistribute it and/or modify
 * it under the terms of the GNU General Public License version 2 and
 * only version 2 as published by the Free Software Foundation.
 *
 * This program is distributed in the hope that it will be useful,
 * but WITHOUT ANY WARRANTY; without even the implied warranty of
 * MERCHANTABILITY or FITNESS FOR A PARTICULAR PURPOSE.  See the
 * GNU General Public License for more details.
 */

&pio {
	nfc_ven: nfc_ven {
		pins_cmd_dat{
			pinmux = <MTK_PINMUX(SEC_GPIO_NUM(AP,pio,136), 0)>;
			output-high;
			bias-disable;
		};
	};
	ven_nc: ven_nc {
		pins_cmd_dat{
			pinmux = <MTK_PINMUX(SEC_GPIO_NUM(AP,pio,136), 0)>;
			input-enable;
			bias-pull-down;
		};
	};
};

&pio {
	nfc_firm: nfc_firm {
		pins_cmd_dat{
			pinmux = <MTK_PINMUX(SEC_GPIO_NUM(AP,pio,137), 0)>;
			output-low;
			bias-disable;
		};
	};
	firm_nc: firm_nc {
		pins_cmd_dat{
			pinmux = <MTK_PINMUX(SEC_GPIO_NUM(AP,pio,137), 0)>;
			input-enable;
			bias-pull-down;
		};
	};
};

&pio {
	nfc_clk_req: nfc_clk_req {
		pins_cmd_dat{
			pinmux =  <MTK_PINMUX(SEC_GPIO_NUM(AP,pio,13), 0)>;
			input-enable;
			bias-pull-down;
		};
	};
	clk_req_nc: clk_req_nc {
		pins_cmd_dat{
			pinmux =  <MTK_PINMUX(SEC_GPIO_NUM(AP,pio,13), 0)>;
			input-enable;
			bias-pull-down;
		};
	};
};

&pio {
	nfc_irq: nfc_irq {
		pins_cmd_dat {
			pinmux = <MTK_PINMUX(SEC_GPIO_NUM(AP,pio,5), 0)>;
			input-enable;
			bias-pull-down;
		};
	};

	irq_nc: irq_nc {
		pins_cmd_dat {
			pinmux = <MTK_PINMUX(SEC_GPIO_NUM(AP,pio,5), 0)>;
			input-enable;
			bias-pull-down;
		};
	};
};

#if 0
&${nfc_check_parent} {
	nfc_check: nfc_check {
		pins_cmd_dat {
			pinmux = <MTK_PINMUX(SEC_GPIO_NUM(${nfc_check}), 0)>;
			input-enable;
			bias-disable;
		};
	};
};
#endif

#if 0
&${sw_parent} {
	nfc_sw: nfc_sw {
		pins_cmd_dat {
			pinmux = <MTK_PINMUX(SEC_GPIO_NUM(${sw_gpio}), 0)>;
			output-low;
			bias-disable;
		};
	};
	sw_nc: sw_nc {
		pins_cmd_dat {
			pinmux = <MTK_PINMUX(SEC_GPIO_NUM(${sw_gpio}), 0)>;
			input-enable;
			bias-pull-down;
		};
	};
};
#endif

&i2c3 {
	status = "ok";
	clock-frequency = <400000>;
	mediatek,use-open-drain;
	sec-nfc@27 {
		compatible = "sec-nfc";
		reg = <0x27>;
		interrupt-parent = <&pio>;
		interrupts = <SEC_GPIO_NUM(AP,pio,5) IRQ_TYPE_EDGE_RISING
			SEC_GPIO_NUM(AP,pio,5) 0>;
		sec-nfc,irq-gpio = <SEC_GPIO_REF(AP,pio,5) 0>;
		sec-nfc,ven-gpio = <SEC_GPIO_REF(AP,pio,136) 0>;
		sec-nfc,firm-gpio = <SEC_GPIO_REF(AP,pio,137) 0>;
		sec-nfc,clk_req-gpio = <SEC_GPIO_REF(AP,pio,13) 0>;
#if 1
		nfc_pvdd-supply = <&mt_pmic_vfp_ldo_reg>;
#endif
#if 0
		sec-nfc,check_nfc = <SEC_GPIO_REF(${nfc_check}) 0>;
#endif
		sec-nfc,clk_req_wake;
		sec-nfc,ldo_control;
/*		sec-nfc,pvdd-gpio = <&pio 154 0>;*/
#if 0
		sec-nfc,sw-gpio = <SEC_GPIO_REF(${sw_gpio}) 0>;
#endif
		sec-nfc,bootloader_ver = <6>;
		/*sec-nfc,irq_all_trigger;*/
		pinctrl-names = "default", "nfc_nc";

		pinctrl-0 = <&nfc_ven &nfc_firm &nfc_clk_req &nfc_irq
#if 0
					&nfc_check 
#endif
#if 0
					&nfc_sw
#endif
					>;
		pinctrl-1 = <&ven_nc &firm_nc &clk_req_nc &irq_nc
#if 0
					&sw_nc
#endif
					>;
	};
};

/* #include "../sensorhub_mt6853.dtsi" */            /* From sensorhub_mt6853.py */
/ {
    fragment@model {
        target-path = "/";
        __overlay__ {
            ssp {
                compatible = "ssp";
            };
        };
    };
};
/* /home/dpi/qb5_8815/workspace/P4_1716/android/kernel/kmodule/sensorhub/mtk/mt6853/dts/sensorhub_mt6853.a32x.dtsi */
/ {
    fragment@model {
        target-path = "/";
        __overlay__ {
            ssp {
                ssp-acc-position = <0>;
                ssp-mag-position = <2>;
                ssp-acc-motor-coef = <5>;
                ssp-mag-array = /bits/ 16 <9689 (-190) (-385) 114 11577 (-298) 234 (-681) 10972>;
                ssp-prox-thresh = /bits/ 16 <150 130>;
                ssp-light-position = /bits/ 32 <46 27 3 21 2 8>;
                ssp-brightness-array-len = <5>;
                ssp-brightness-array = /bits/ 32 <15 40 50 77 255>;
                ssp-light-cam-lux = /bits/ 32 <100 200>;
                ssp-light-cam-br = /bits/ 32 <60 60>;
            };
        };
    };
};
/* /home/dpi/qb5_8815/workspace/P4_1716/android/kernel/kmodule/sensorhub/mtk/mt6853/dts/sensorhub_mt6853.a32x.03.dtsi */
/ {
    fragment@model {
        target-path = "/";
        __overlay__ {
            ssp {
                ssp-acc-position = <4>;
                ssp-mag-position = <2>;
                ssp-mag-array = /bits/ 16 <9689 (-190) (-385) 114 11577 (-298) 234 (-681) 10972>;
                ssp-prox-thresh = /bits/ 16 <150 130>;
                ssp-light-position = /bits/ 32 <46 27 3 21 2 8>;
                ssp-brightness-array-len = <5>;
                ssp-brightness-array = /bits/ 32 <15 40 50 77 255>;
                ssp-light-cam-lux = /bits/ 32 <100 200>;
                ssp-light-cam-br = /bits/ 32 <60 60>;
            };
        };
    };
};
/* revision devicetree for general */
#include "mt6853.a32x_eur_open.03.dtsi"

/ {
	compatible = "Samsung,A32x EUR OPEN 03","Mediatek,MT6853";
	dtbo-hw_rev = <3>;
	dtbo-hw_rev_end = <4>;
};
